VERSION ""

BA_DEF_ SG_ "CSV_ORDER" INT 0 10000;
BA_DEF_DEF_ "CSV_ORDER" 0;

NS_ :

BS_:

BU_:

BO_ 3221225472 VECTOR__INDEPENDENT_SIG_MSG: 0 Vector__XXX
 SG_ ChargerVoltage : 0|16@0+ (0.1,0) [0|6553.5] "" Vector__XXX
 SG_ ChargerCurrent : 0|16@0+ (0.1,0) [0|6553.5] "Amps" Vector__XXX

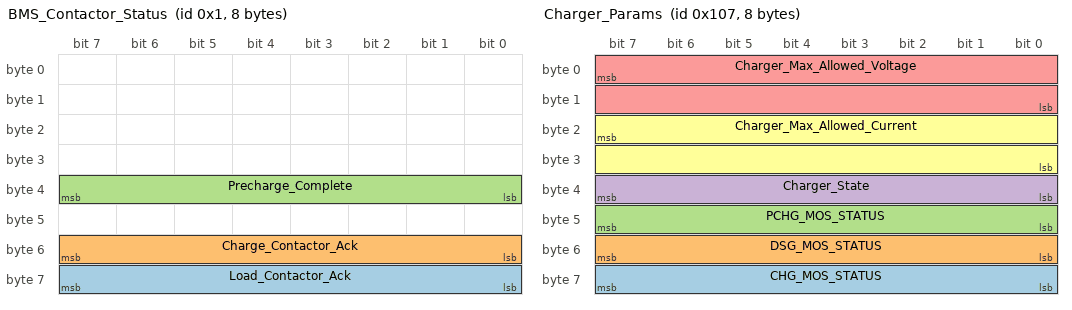
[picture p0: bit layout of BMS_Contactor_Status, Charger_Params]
BO_ 1 BMS_Contactor_Status: 8 Vector__XXX
 SG_ Load_Contactor_Ack : 56|8@1+ (1,0) [0|1] "" Vector__XXX
 SG_ Charge_Contactor_Ack : 48|8@1+ (1,0) [0|1] "" Vector__XXX
 SG_ Precharge_Complete : 32|8@1+ (1,0) [0|1] "" Vector__XXX

BO_ 263 Charger_Params: 8 Vector__XXX
 SG_ CHG_MOS_STATUS : 56|8@1- (1,0) [0|0] "" Vector__XXX
 SG_ DSG_MOS_STATUS : 48|8@1- (1,0) [0|0] "" Vector__XXX
 SG_ PCHG_MOS_STATUS : 40|8@1- (1,0) [0|0] "" Vector__XXX
 SG_ Charger_State : 39|8@0+ (1,0) [0|0] "" Vector__XXX
 SG_ Charger_Max_Allowed_Voltage : 7|16@0+ (0.1,0) [0|0] "V" Vector__XXX
 SG_ Charger_Max_Allowed_Current : 23|16@0+ (0.1,0) [0|0] "A" Vector__XXX

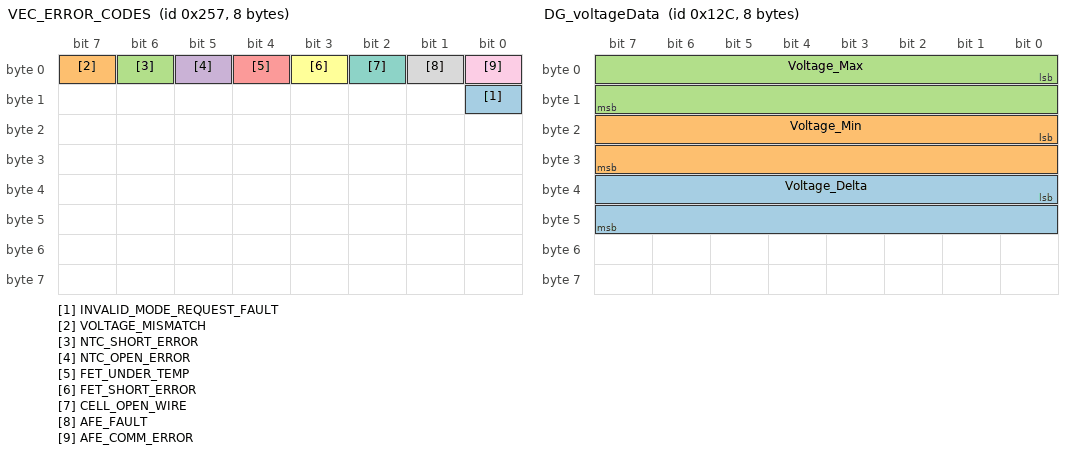
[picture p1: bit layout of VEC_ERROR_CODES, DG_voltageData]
BO_ 599 VEC_ERROR_CODES: 8 Vector__XXX
 SG_ INVALID_MODE_REQUEST_FAULT : 8|1@1+ (1,0) [0|1] "" Vector__XXX
 SG_ VOLTAGE_MISMATCH          : 7|1@1+ (1,0) [0|1] "" Vector__XXX
 SG_ NTC_SHORT_ERROR           : 6|1@1+ (1,0) [0|1] "" Vector__XXX
 SG_ NTC_OPEN_ERROR            : 5|1@1+ (1,0) [0|1] "" Vector__XXX
 SG_ FET_UNDER_TEMP            : 4|1@1+ (1,0) [0|1] "" Vector__XXX
 SG_ FET_SHORT_ERROR           : 3|1@1+ (1,0) [0|1] "" Vector__XXX
 SG_ CELL_OPEN_WIRE            : 2|1@1+ (1,0) [0|1] "" Vector__XXX
 SG_ AFE_FAULT                 : 1|1@1+ (1,0) [0|1] "" Vector__XXX
 SG_ AFE_COMM_ERROR            : 0|1@1+ (1,0) [0|1] "" Vector__XXX

BO_ 336 BalancingMasks: 8 Vector__XXX
 SG_ BalancingMaskGroup1 : 0|8@1+ (1,0) [0|255] "" Vector__XXX
 SG_ BalancingMaskGroup2 : 8|8@1+ (1,0) [0|255] "" Vector__XXX

BO_ 300 DG_voltageData: 8 Vector__XXX
 SG_ Voltage_Delta : 32|16@1+ (0.1,0) [0|65535] "mV" Vector__XXX
 SG_ Voltage_Min : 16|16@1+ (0.1,0) [0|65535] "mV" Vector__XXX
 SG_ Voltage_Max : 0|16@1+ (0.1,0) [0|65535] "mV" Vector__XXX

BO_ 342 BC_Dynamic_inst: 8 Vector__XXX
 SG_ dynamicLimitIn_Inst : 0|16@1- (0.1,0) [-3276.8|3276.7] "" Vector__XXX
 SG_ dynamicLimitOut_Inst : 16|16@1- (0.1,0) [-3276.8|3276.7] "A" Vector__XXX

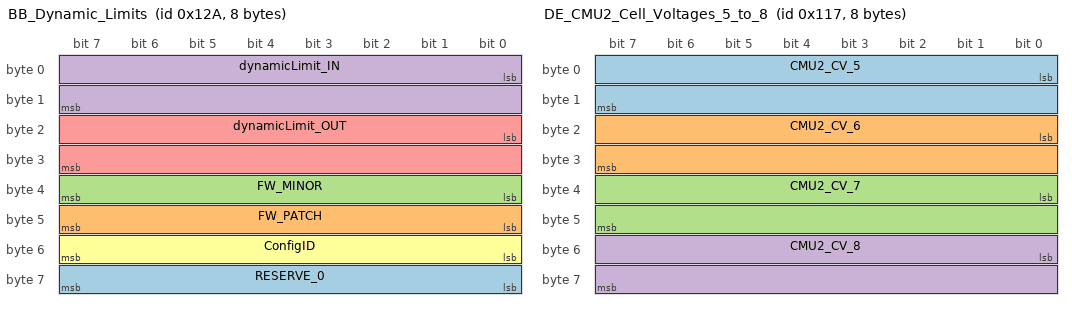
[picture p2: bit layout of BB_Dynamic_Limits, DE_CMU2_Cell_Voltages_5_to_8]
BO_ 298 BB_Dynamic_Limits: 8 Vector__XXX
 SG_ RESERVE_0 : 56|8@1+ (1,0) [0|0] "" Vector__XXX
 SG_ FW_PATCH : 40|8@1+ (1,0) [0|0] "" Vector__XXX
 SG_ FW_MINOR : 32|8@1+ (1,0) [0|0] "" Vector__XXX
 SG_ dynamicLimit_IN : 0|16@1- (0.1,0) [-3276.8|3276.7] "A" Vector__XXX
 SG_ dynamicLimit_OUT : 16|16@1- (0.1,0) [-3276.8|3276.7] "A" Vector__XXX
 SG_ ConfigID : 48|8@1- (1,0) [-128|127] "" Vector__XXX

BO_ 279 DE_CMU2_Cell_Voltages_5_to_8: 8 Vector__XXX
 SG_ CMU2_CV_5 : 0|16@1+ (0.1,0) [0|4200] "mV" Vector__XXX
 SG_ CMU2_CV_6 : 16|16@1+ (0.1,0) [0|4200] "mV" Vector__XXX
 SG_ CMU2_CV_7 : 32|16@1+ (0.1,0) [0|4200] "mV" Vector__XXX
 SG_ CMU2_CV_8 : 48|16@1+ (0.1,0) [0|4200] "mV" Vector__XXX

BO_ 299 BF_CCM_CMU_Counter: 8 Vector__XXX
 SG_ cycleCount : 48|16@1+ (1,0) [0|65535] "" Vector__XXX
 SG_ mcu_counter : 16|16@1+ (1,0) [0|65535] "" Vector__XXX

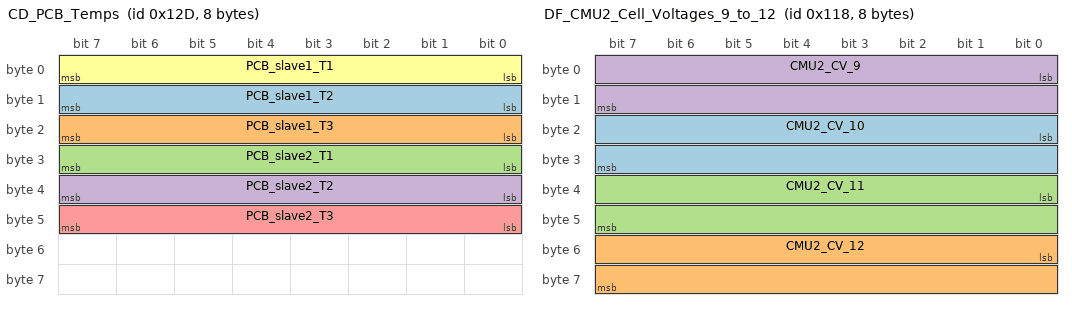
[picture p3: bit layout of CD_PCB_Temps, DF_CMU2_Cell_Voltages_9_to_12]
BO_ 301 CD_PCB_Temps: 8 Vector__XXX
 SG_ PCB_slave1_T2 : 8|8@1- (1,0) [-128|127] "C" Vector__XXX
 SG_ PCB_slave1_T3 : 16|8@1- (1,0) [-128|127] "C" Vector__XXX
 SG_ PCB_slave2_T1 : 24|8@1- (1,0) [-128|127] "C" Vector__XXX
 SG_ PCB_slave2_T2 : 32|8@1- (1,0) [-128|127] "C" Vector__XXX
 SG_ PCB_slave2_T3 : 40|8@1- (1,0) [-128|127] "C" Vector__XXX
 SG_ PCB_slave1_T1 : 0|8@1- (1,0) [-128|127] "C" Vector__XXX

BO_ 280 DF_CMU2_Cell_Voltages_9_to_12: 8 Vector__XXX
 SG_ CMU2_CV_10 : 16|16@1+ (0.1,0) [0|4200] "mV" Vector__XXX
 SG_ CMU2_CV_12 : 48|16@1+ (0.1,0) [0|4200] "mV" Vector__XXX
 SG_ CMU2_CV_11 : 32|16@1+ (0.1,0) [0|4200] "mV" Vector__XXX
 SG_ CMU2_CV_9 : 0|16@1+ (0.1,0) [0|4200] "mV" Vector__XXX

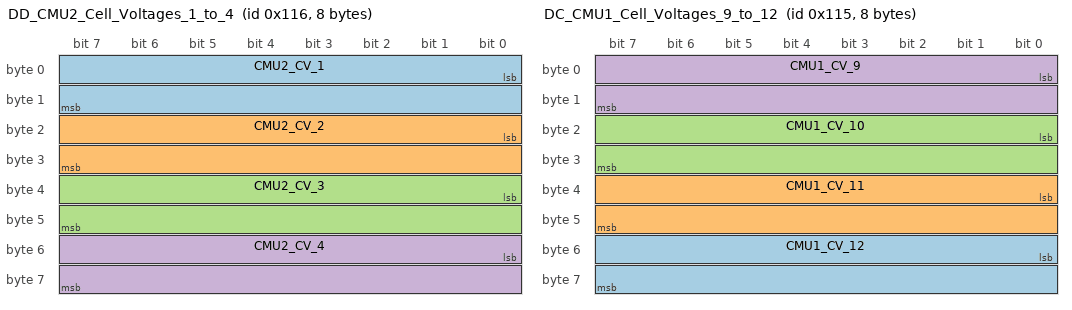
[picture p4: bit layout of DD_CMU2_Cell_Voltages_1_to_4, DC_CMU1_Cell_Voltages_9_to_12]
BO_ 278 DD_CMU2_Cell_Voltages_1_to_4: 8 Vector__XXX
 SG_ CMU2_CV_1 : 0|16@1+ (0.1,0) [0|4200] "mV" Vector__XXX
 SG_ CMU2_CV_2 : 16|16@1+ (0.1,0) [0|4200] "mV" Vector__XXX
 SG_ CMU2_CV_3 : 32|16@1+ (0.1,0) [0|4200] "mV" Vector__XXX
 SG_ CMU2_CV_4 : 48|16@1+ (0.1,0) [0|4200] "mV" Vector__XXX

BO_ 277 DC_CMU1_Cell_Voltages_9_to_12: 8 Vector__XXX
 SG_ CMU1_CV_12 : 48|16@1+ (0.1,0) [0|4200] "mV" Vector__XXX
 SG_ CMU1_CV_11 : 32|16@1+ (0.1,0) [0|4200] "mV" Vector__XXX
 SG_ CMU1_CV_10 : 16|16@1+ (0.1,0) [0|4200] "mV" Vector__XXX
 SG_ CMU1_CV_9 : 0|16@1+ (0.1,0) [0|4200] "mV" Vector__XXX

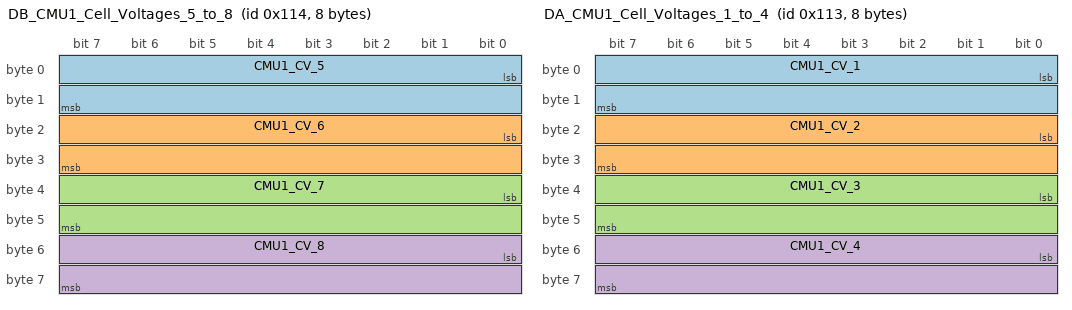
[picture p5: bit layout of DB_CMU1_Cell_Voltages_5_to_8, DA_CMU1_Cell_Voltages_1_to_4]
BO_ 276 DB_CMU1_Cell_Voltages_5_to_8: 8 Vector__XXX
 SG_ CMU1_CV_5 : 0|16@1+ (0.1,0) [0|4200] "mV" Vector__XXX
 SG_ CMU1_CV_6 : 16|16@1+ (0.1,0) [0|4200] "mV" Vector__XXX
 SG_ CMU1_CV_7 : 32|16@1+ (0.1,0) [0|4200] "mV" Vector__XXX
 SG_ CMU1_CV_8 : 48|16@1+ (0.1,0) [0|4200] "mV" Vector__XXX

BO_ 275 DA_CMU1_Cell_Voltages_1_to_4: 8 Vector__XXX
 SG_ CMU1_CV_1 : 0|16@1+ (0.1,0) [0|4200] "mV" Vector__XXX
 SG_ CMU1_CV_2 : 16|16@1+ (0.1,0) [0|4200] "mV" Vector__XXX
 SG_ CMU1_CV_3 : 32|16@1+ (0.1,0) [0|4200] "mV" Vector__XXX
 SG_ CMU1_CV_4 : 48|16@1+ (0.1,0) [0|4200] "mV" Vector__XXX

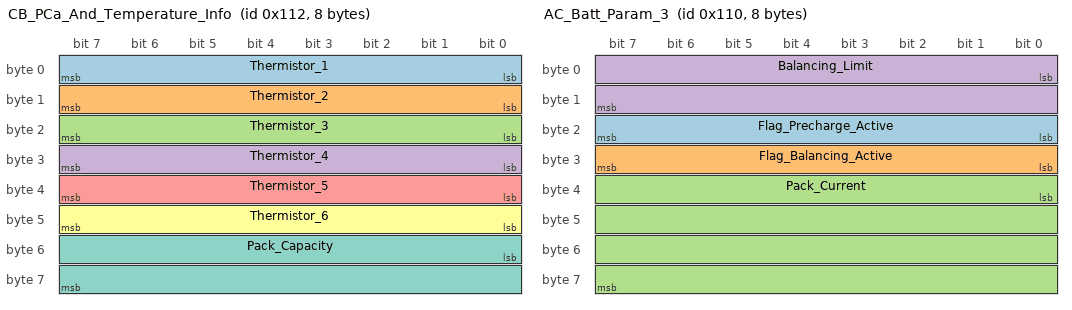
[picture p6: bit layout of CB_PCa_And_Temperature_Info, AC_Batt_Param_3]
BO_ 274 CB_PCa_And_Temperature_Info: 8 Vector__XXX
 SG_ Thermistor_1 : 0|8@1- (1,0) [-128|127] "C" Vector__XXX
 SG_ Thermistor_2 : 8|8@1- (1,0) [-128|127] "C" Vector__XXX
 SG_ Thermistor_3 : 16|8@1- (1,0) [-128|127] "C" Vector__XXX
 SG_ Thermistor_4 : 24|8@1- (1,0) [-128|127] "C" Vector__XXX
 SG_ Thermistor_5 : 32|8@1- (1,0) [-128|127] "C" Vector__XXX
 SG_ Thermistor_6 : 40|8@1- (1,0) [-128|127] "C" Vector__XXX
 SG_ Pack_Capacity : 48|16@1- (0.01,0) [-327.68|327.67] "Ah" Vector__XXX

BO_ 272 AC_Batt_Param_3: 8 Vector__XXX
 SG_ Flag_Precharge_Active : 16|8@1+ (1,0) [0|1] "" Vector__XXX
 SG_ Flag_Balancing_Active : 24|8@1+ (1,0) [0|1] "" Vector__XXX
 SG_ Pack_Current : 32|32@1- (1E-05,0) [-1000|1000] "A" Vector__XXX
 SG_ Balancing_Limit : 0|16@1+ (0.1,0) [0|4200] "mV" Vector__XXX

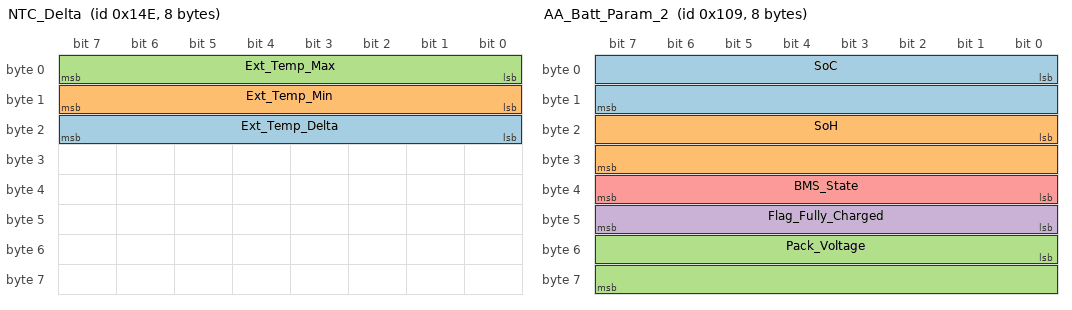
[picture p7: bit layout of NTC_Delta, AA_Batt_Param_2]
BO_ 334 NTC_Delta: 8 Vector__XXX
 SG_ Ext_Temp_Delta : 16|8@1- (1,0) [0|255] "degC" Vector__XXX
 SG_ Ext_Temp_Min   : 8|8@1- (1,0) [0|255] "degC" Vector__XXX
 SG_ Ext_Temp_Max   : 0|8@1- (1,0) [0|255] "degC" Vector__XXX

BO_ 265 AA_Batt_Param_2: 8 Vector__XXX
 SG_ SoC : 0|16@1+ (0.01,0) [0|100] "%" Vector__XXX
 SG_ SoH : 16|16@1+ (0.01,0) [0|100] "%" Vector__XXX
 SG_ Pack_Voltage : 48|16@1+ (0.1,0) [60|85] "V" Vector__XXX
 SG_ Flag_Fully_Charged : 40|8@1+ (1,0) [0|1] "" Vector__XXX
 SG_ BMS_State : 32|8@1+ (1,0) [0|5] "" Vector__XXX

VAL_ 265 Flag_Fully_Charged  0 "False" 1 "True" ;
VAL_ 265 BMS_State           0 "INIT" 1 "Ready" 2 "Precharge" 3 "Active" 4 "Error" ;

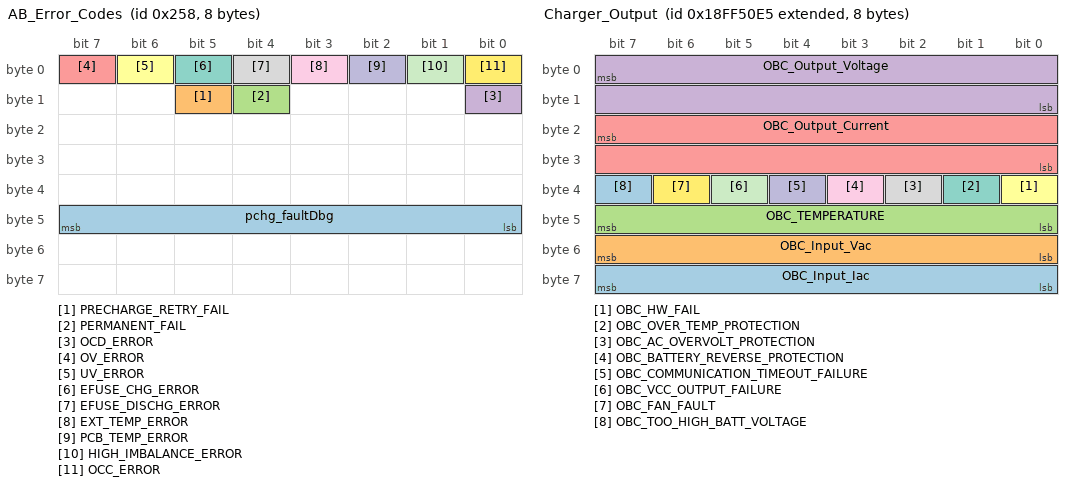
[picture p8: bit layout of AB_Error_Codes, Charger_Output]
BO_ 600 AB_Error_Codes: 8 Vector__XXX
 SG_ pchg_faultDbg          : 40|8@1+ (1,0) [0|255] "" Vector__XXX
 SG_ PRECHARGE_RETRY_FAIL   : 13|1@1+ (1,0) [0|1] "" Vector__XXX
 SG_ PERMANENT_FAIL : 12|1@1+ (1,0) [0|0] "" Vector__XXX
 SG_ OCD_ERROR              : 8|1@1+ (1,0) [0|1] "" Vector__XXX
 SG_ OV_ERROR               : 7|1@1+ (1,0) [0|1] "" Vector__XXX
 SG_ UV_ERROR               : 6|1@1+ (1,0) [0|1] "" Vector__XXX
 SG_ EFUSE_CHG_ERROR        : 5|1@1+ (1,0) [0|1] "" Vector__XXX
 SG_ EFUSE_DISCHG_ERROR     : 4|1@1+ (1,0) [0|1] "" Vector__XXX
 SG_ EXT_TEMP_ERROR         : 3|1@1+ (1,0) [0|1] "" Vector__XXX
 SG_ PCB_TEMP_ERROR         : 2|1@1+ (1,0) [0|1] "" Vector__XXX
 SG_ HIGH_IMBALANCE_ERROR   : 1|1@1+ (1,0) [0|1] "" Vector__XXX
 SG_ OCC_ERROR              : 0|1@1+ (1,0) [0|1] "" Vector__XXX

BO_ 601 Critical_Error: 8 Vector__XXX
 SG_ THERMAL_RUNAWAY : 6|1@1+ (1,0) [0|1] "" Vector__XXX
 SG_ SCD_ERROR : 7|1@1+ (1,0) [0|1] "" Vector__XXX

BO_ 2566869221 Charger_Output: 8 Vector__XXX
 SG_ OBC_Input_Iac : 63|8@0+ (0.1,0) [0|25.5] "A" Vector__XXX
 SG_ OBC_Input_Vac : 55|8@0+ (2,0) [0|510] "V" Vector__XXX
 SG_ OBC_TEMPERATURE : 47|8@0+ (1,-100) [-100|155] "°C" Vector__XXX
 SG_ OBC_Output_Voltage : 7|16@0+ (0.1,0) [0|6553.5] "V" Vector__XXX
 SG_ OBC_Output_Current : 23|16@0+ (0.1,0) [0|6553.5] "A" Vector__XXX
 SG_ OBC_HW_FAIL : 32|1@0- (1,0) [0|1] "" Vector__XXX
 SG_ OBC_OVER_TEMP_PROTECTION : 33|1@0- (1,0) [0|1] "" Vector__XXX
 SG_ OBC_AC_OVERVOLT_PROTECTION : 34|1@0- (1,0) [0|1] "" Vector__XXX
 SG_ OBC_BATTERY_REVERSE_PROTECTION : 35|1@0- (1,0) [0|1] "" Vector__XXX
 SG_ OBC_COMMUNICATION_TIMEOUT_FAILURE : 36|1@0- (1,0) [0|1] "" Vector__XXX
 SG_ OBC_VCC_OUTPUT_FAILURE : 37|1@0- (1,0) [0|1] "" Vector__XXX
 SG_ OBC_FAN_FAULT : 38|1@0- (1,0) [0|1] "" Vector__XXX
 SG_ OBC_TOO_HIGH_BATT_VOLTAGE : 39|1@0- (1,0) [0|1] "" Vector__XXX

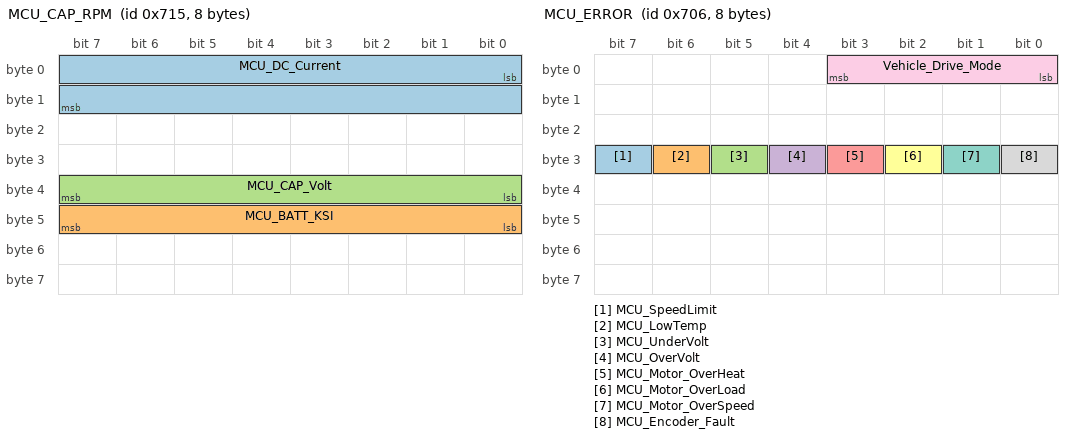
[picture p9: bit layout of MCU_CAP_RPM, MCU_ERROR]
BO_ 1813 MCU_CAP_RPM: 8 Vector__XXX
 SG_ MCU_DC_Current : 0|16@1- (1,0) [-32768|32767] "Adc" Vector__XXX
 SG_ MCU_BATT_KSI : 40|8@1+ (1,0) [0|255] "V" Vector__XXX
 SG_ MCU_CAP_Volt : 32|8@1+ (1,0) [0|255] "V" Vector__XXX

BO_ 1798 MCU_ERROR: 8 Vector__XXX
 SG_ MCU_SpeedLimit : 31|1@1+ (1,0) [0|1] "" Vector__XXX
 SG_ MCU_LowTemp : 30|1@1+ (1,0) [0|1] "" Vector__XXX
 SG_ MCU_UnderVolt : 29|1@1+ (1,0) [0|1] "" Vector__XXX
 SG_ MCU_OverVolt : 28|1@1+ (1,0) [0|1] "" Vector__XXX
 SG_ MCU_Motor_OverHeat : 27|1@1+ (1,0) [0|1] "" Vector__XXX
 SG_ MCU_Motor_OverLoad : 26|1@1+ (1,0) [0|1] "" Vector__XXX
 SG_ MCU_Motor_OverSpeed : 25|1@1+ (1,0) [0|1] "" Vector__XXX
 SG_ MCU_Encoder_Fault : 24|1@1+ (1,0) [0|1] "" Vector__XXX
 SG_ Vehicle_Drive_Mode : 0|4@1+ (1,0) [0|15] "" Vector__XXX

VAL_ 1798 Vehicle_Drive_Mode 1 "NEUTRAL" 2 "ECO" 4 "REVERSE" 8 "THUNDER" ;

BO_ 1800 New_Message_10: 8 Vector__XXX
 SG_ hardware_overvoltage : 10|1@1+ (1,0) [0|1] "" Vector__XXX
 SG_ Hardware_overcurrent : 4|1@1+ (1,0) [0|1] "" Vector__XXX

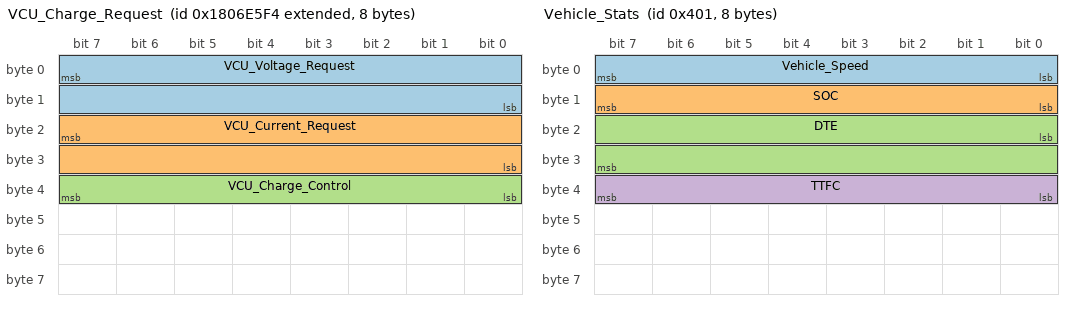
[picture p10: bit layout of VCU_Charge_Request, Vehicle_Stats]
BO_ 2550588916 VCU_Charge_Request: 8 Vector__XXX
 SG_ VCU_Voltage_Request : 7|16@0+ (0.1,0) [0|6553.5] "V" Vector__XXX
 SG_ VCU_Current_Request : 23|16@0+ (0.1,0) [0|6553.5] "A" Vector__XXX
 SG_ VCU_Charge_Control  : 39|8@0+ (1,0) [0|1] "" Vector__XXX

BO_ 1025 Vehicle_Stats: 8 Vector__XXX
 SG_ Vehicle_Speed : 0|8@1+ (1,0) [0|255] "km/h" Vector__XXX
 SG_ SOC           : 8|8@1+ (1,0) [0|100] "%"    Vector__XXX
 SG_ DTE           : 16|16@1+ (0.1,0) [0|6553.5] "min" Vector__XXX
 SG_ TTFC          : 32|8@1+ (1,0) [0|255] "min" Vector__XXX

BO_ 1026 ODO_TRIP: 8 Vector__XXX
 SG_ ODO  : 0|32@1+ (0.1,0) [0|429496729.5] "km" Vector__XXX
 SG_ TRIP : 32|32@1+ (0.1,0) [0|429496729.5] "km" Vector__XXX

BO_ 1033 Odo: 8 Vector__XXX
 SG_ odometer : 7|32@0+ (0.01,0) [0|0] "" Vector__XXX
 SG_ trip : 39|32@0+ (0.01,0) [0|0] "" Vector__XXX

BO_ 1776 Reset: 8 Vector__XXX
 SG_ EcuId : 0|8@1+ (1,0) [0|0] "" Vector__XXX

VAL_ 1776 EcuId 0 "Stark_Reset" 2 "Marvel_Reset" 4 "Xavier_Reset" ;

BO_ 1538 State: 8 Vector__XXX
 SG_ gunConnected : 48|8@1- (1,0) [0|0] "" Vector__XXX
 SG_ VehicleState : 56|8@1+ (1,0) [0|0] "" Vector__XXX

VAL_ 1538 VehicleState           0 "Off" 1 "Charge" 2 "Drive" 3 "Full Charge" 4 "Deep_Sleep/OTA" 5 "Accessories_Mode" ;

BO_ 1542 AuxVoltage: 8 Vector__XXX
 SG_ Aux_Voltage : 15|16@0+ (0.01,0) [0|655.35] "V" Vector__XXX

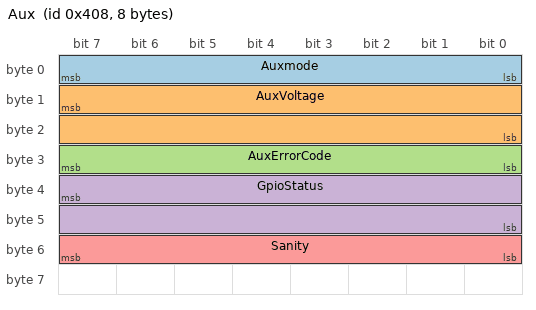
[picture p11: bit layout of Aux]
BO_ 1032 Aux: 8 Vector__XXX
 SG_ Auxmode      : 7|8@0+  (1,0)     [0|255] "" Vector__XXX
 SG_ AuxVoltage   : 15|16@0+ (0.01,0) [0|655.35] "" Vector__XXX
 SG_ AuxErrorCode : 31|8@0+  (1,0)     [0|255] "" Vector__XXX
 SG_ GpioStatus   : 39|16@0+ (1,0)     [0|65535] "" Vector__XXX
 SG_ Sanity       : 55|8@0+  (1,0)     [0|255] "" Vector__XXX

VAL_ 1032 Auxmode 0 "AUX_IDLE" 1 "AUX_CHARGE_START" 2 "AUX_CHARGING" 3 "AUX_SLEEPING" 4 "AUX_ERROR" ;
VAL_ 1032 GpioStatus 0 "ALL_OFF" 1 "(BMS)_ON" 2 "(MCU)_ON" 3 "(BMS+MCU)_ON" 4 "(DC_DC)_ON" 5 "(BMS+DC_DC)_ON" 6 "(MCU+DC_DC)_ON" 7 "(BMS+MCU+DC_DC)_ON" 8 "(HB)_ON" 9 "(BMS+HB)_ON" 10 "(MCU+HB)_ON" 11 "(BMS+MCU+HB)_ON" 12 "(DC_DC+HB)_ON" 13 "(BMS+DC_DC+HB)_ON" 14 "(MCU+DC_DC+HB)_ON" 15 "(BMS+MCU+DC_DC+HB)_ON" 16 "(LB)_ON" 17 "(BMS+LB)_ON" 18 "(MCU+LB)_ON" 19 "(BMS+MCU+LB)_ON" 20 "(DC_DC+LB)_ON" 21 "(BMS+DC_DC+LB)_ON" 22 "(MCU+DC_DC+LB)_ON" 23 "(BMS+MCU+DC_DC+LB)_ON" 24 "(HB+LB)_ON" 25 "(BMS+HB+LB)_ON" 26 "(MCU+HB+LB)_ON" 27 "(BMS+MCU+HB+LB)_ON" 28 "(DC_DC+HB+LB)_ON" 29 "(BMS+DC_DC+HB+LB)_ON" 30 "(MCU+DC_DC+HB+LB)_ON" 31 "(BMS+MCU+DC_DC+HB+LB)_ON" 32 "(CHARGE)_ON" 33 "(BMS+CHARGE)_ON" 34 "(MCU+CHARGE)_ON" 35 "(BMS+MCU+CHARGE)_ON" 36 "(DC_DC+CHARGE)_ON" 37 "(BMS+DC_DC+CHARGE)_ON" 38 "(MCU+DC_DC+CHARGE)_ON" 39 "(BMS+MCU+DC_DC+CHARGE)_ON" 40 "(HB+CHARGE)_ON" 41 "(BMS+HB+CHARGE)_ON" 42 "(MCU+HB+CHARGE)_ON" 43 "(BMS+MCU+HB+CHARGE)_ON" 44 "(DC_DC+HB+CHARGE)_ON" 45 "(BMS+DC_DC+HB+CHARGE)_ON" 46 "(MCU+DC_DC+HB+CHARGE)_ON" 47 "(BMS+MCU+DC_DC+HB+CHARGE)_ON" 48 "(LB+CHARGE)_ON" 49 "(BMS+LB+CHARGE)_ON" 50 "(MCU+LB+CHARGE)_ON" 51 "(BMS+MCU+LB+CHARGE)_ON" 52 "(DC_DC+LB+CHARGE)_ON" 53 "(BMS+DC_DC+LB+CHARGE)_ON" 54 "(MCU+DC_DC+LB+CHARGE)_ON" 55 "(BMS+MCU+DC_DC+LB+CHARGE)_ON" 56 "(HB+LB+CHARGE)_ON" 57 "(BMS+HB+LB+CHARGE)_ON" 58 "(MCU+HB+LB+CHARGE)_ON" 59 "(BMS+MCU+HB+LB+CHARGE)_ON" 60 "(DC_DC+HB+LB+CHARGE)_ON" 61 "(BMS+DC_DC+HB+LB+CHARGE)_ON" 62 "(MCU+DC_DC+HB+LB+CHARGE)_ON" 63 "(BMS+MCU+DC_DC+HB+LB+CHARGE)_ON" 64 "(LOAD)_ON" 65 "(BMS+LOAD)_ON" 66 "(MCU+LOAD)_ON" 67 "(BMS+MCU+LOAD)_ON" 68 "(DC_DC+LOAD)_ON" 69 "(BMS+DC_DC+LOAD)_ON" 70 "(MCU+DC_DC+LOAD)_ON" 71 "(BMS+MCU+DC_DC+LOAD)_ON" 72 "(HB+LOAD)_ON" 73 "(BMS+HB+LOAD)_ON" 74 "(MCU+HB+LOAD)_ON" 75 "(BMS+MCU+HB+LOAD)_ON" 76 "(DC_DC+HB+LOAD)_ON" 77 "(BMS+DC_DC+HB+LOAD)_ON" 78 "(MCU+DC_DC+HB+LOAD)_ON" 79 "(BMS+MCU+DC_DC+HB+LOAD)_ON" 80 "(LB+LOAD)_ON" 81 "(BMS+LB+LOAD)_ON" 82 "(MCU+LB+LOAD)_ON" 83 "(BMS+MCU+LB+LOAD)_ON" 84 "(DC_DC+LB+LOAD)_ON" 85 "(BMS+DC_DC+LB+LOAD)_ON" 86 "(MCU+DC_DC+LB+LOAD)_ON" 87 "(BMS+MCU+DC_DC+LB+LOAD)_ON" 88 "(HB+LB+LOAD)_ON" 89 "(BMS+HB+LB+LOAD)_ON" 90 "(MCU+HB+LB+LOAD)_ON" 91 "(BMS+MCU+HB+LB+LOAD)_ON" 92 "(DC_DC+HB+LB+LOAD)_ON" 93 "(BMS+DC_DC+HB+LB+LOAD)_ON" 94 "(MCU+DC_DC+HB+LB+LOAD)_ON" 95 "(BMS+MCU+DC_DC+HB+LB+LOAD)_ON" 96 "(CHARGE+LOAD)_ON" 97 "(BMS+CHARGE+LOAD)_ON" 98 "(MCU+CHARGE+LOAD)_ON" 99 "(BMS+MCU+CHARGE+LOAD)_ON" 100 "(DC_DC+CHARGE+LOAD)_ON" 101 "(BMS+DC_DC+CHARGE+LOAD)_ON" 102 "(MCU+DC_DC+CHARGE+LOAD)_ON" 103 "(BMS+MCU+DC_DC+CHARGE+LOAD)_ON" 104 "(HB+CHARGE+LOAD)_ON" 105 "(BMS+HB+CHARGE+LOAD)_ON" 106 "(MCU+HB+CHARGE+LOAD)_ON" 107 "(BMS+MCU+HB+CHARGE+LOAD)_ON" 108 "(DC_DC+HB+CHARGE+LOAD)_ON" 109 "(BMS+DC_DC+HB+CHARGE+LOAD)_ON" 110 "(MCU+DC_DC+HB+CHARGE+LOAD)_ON" 111 "(BMS+MCU+DC_DC+HB+CHARGE+LOAD)_ON" 112 "(LB+CHARGE+LOAD)_ON" 113 "(BMS+LB+CHARGE+LOAD)_ON" 114 "(MCU+LB+CHARGE+LOAD)_ON" 115 "(BMS+MCU+LB+CHARGE+LOAD)_ON" 116 "(DC_DC+LB+CHARGE+LOAD)_ON" 117 "(BMS+DC_DC+LB+CHARGE+LOAD)_ON" 118 "(MCU+DC_DC+LB+CHARGE+LOAD)_ON" 119 "(BMS+MCU+DC_DC+LB+CHARGE+LOAD)_ON" 120 "(HB+LB+CHARGE+LOAD)_ON" 121 "(BMS+HB+LB+CHARGE+LOAD)_ON" 122 "(MCU+HB+LB+CHARGE+LOAD)_ON" 123 "(BMS+MCU+HB+LB+CHARGE+LOAD)_ON" 124 "(DC_DC+HB+LB+CHARGE+LOAD)_ON" 125 "(BMS+DC_DC+HB+LB+CHARGE+LOAD)_ON" 126 "(MCU+DC_DC+HB+LB+CHARGE+LOAD)_ON" 127 "(BMS+MCU+DC_DC+HB+LB+CHARGE+LOAD)_ON" 128 "(PARK)_ON" 129 "(BMS+PARK)_ON" 130 "(MCU+PARK)_ON" 131 "(BMS+MCU+PARK)_ON" 132 "(DC_DC+PARK)_ON" 133 "(BMS+DC_DC+PARK)_ON" 134 "(MCU+DC_DC+PARK)_ON" 135 "(BMS+MCU+DC_DC+PARK)_ON" 136 "(HB+PARK)_ON" 137 "(BMS+HB+PARK)_ON" 138 "(MCU+HB+PARK)_ON" 139 "(BMS+MCU+HB+PARK)_ON" 140 "(DC_DC+HB+PARK)_ON" 141 "(BMS+DC_DC+HB+PARK)_ON" 142 "(MCU+DC_DC+HB+PARK)_ON" 143 "(BMS+MCU+DC_DC+HB+PARK)_ON" 144 "(LB+PARK)_ON" 145 "(BMS+LB+PARK)_ON" 146 "(MCU+LB+PARK)_ON" 147 "(BMS+MCU+LB+PARK)_ON" 148 "(DC_DC+LB+PARK)_ON" 149 "(BMS+DC_DC+LB+PARK)_ON" 150 "(MCU+DC_DC+LB+PARK)_ON" 151 "(BMS+MCU+DC_DC+LB+PARK)_ON" 152 "(HB+LB+PARK)_ON" 153 "(BMS+HB+LB+PARK)_ON" 154 "(MCU+HB+LB+PARK)_ON" 155 "(BMS+MCU+HB+LB+PARK)_ON" 156 "(DC_DC+HB+LB+PARK)_ON" 157 "(BMS+DC_DC+HB+LB+PARK)_ON" 158 "(MCU+DC_DC+HB+LB+PARK)_ON" 159 "(BMS+MCU+DC_DC+HB+LB+PARK)_ON" 160 "(CHARGE+PARK)_ON" 161 "(BMS+CHARGE+PARK)_ON" 162 "(MCU+CHARGE+PARK)_ON" 163 "(BMS+MCU+CHARGE+PARK)_ON" 164 "(DC_DC+CHARGE+PARK)_ON" 165 "(BMS+DC_DC+CHARGE+PARK)_ON" 166 "(MCU+DC_DC+CHARGE+PARK)_ON" 167 "(BMS+MCU+DC_DC+CHARGE+PARK)_ON" 168 "(HB+CHARGE+PARK)_ON" 169 "(BMS+HB+CHARGE+PARK)_ON" 170 "(MCU+HB+CHARGE+PARK)_ON" 171 "(BMS+MCU+HB+CHARGE+PARK)_ON" 172 "(DC_DC+HB+CHARGE+PARK)_ON" 173 "(BMS+DC_DC+HB+CHARGE+PARK)_ON" 174 "(MCU+DC_DC+HB+CHARGE+PARK)_ON" 175 "(BMS+MCU+DC_DC+HB+CHARGE+PARK)_ON" 176 "(LB+CHARGE+PARK)_ON" 177 "(BMS+LB+CHARGE+PARK)_ON" 178 "(MCU+LB+CHARGE+PARK)_ON" 179 "(BMS+MCU+LB+CHARGE+PARK)_ON" 180 "(DC_DC+LB+CHARGE+PARK)_ON" 181 "(BMS+DC_DC+LB+CHARGE+PARK)_ON" 182 "(MCU+DC_DC+LB+CHARGE+PARK)_ON" 183 "(BMS+MCU+DC_DC+LB+CHARGE+PARK)_ON" 184 "(HB+LB+CHARGE+PARK)_ON" 185 "(BMS+HB+LB+CHARGE+PARK)_ON" 186 "(MCU+HB+LB+CHARGE+PARK)_ON" 187 "(BMS+MCU+HB+LB+CHARGE+PARK)_ON" 188 "(DC_DC+HB+LB+CHARGE+PARK)_ON" 189 "(BMS+DC_DC+HB+LB+CHARGE+PARK)_ON" 190 "(MCU+DC_DC+HB+LB+CHARGE+PARK)_ON" 191 "(BMS+MCU+DC_DC+HB+LB+CHARGE+PARK)_ON" 192 "(LOAD+PARK)_ON" 193 "(BMS+LOAD+PARK)_ON" 194 "(MCU+LOAD+PARK)_ON" 195 "(BMS+MCU+LOAD+PARK)_ON" 196 "(DC_DC+LOAD+PARK)_ON" 197 "(BMS+DC_DC+LOAD+PARK)_ON" 198 "(MCU+DC_DC+LOAD+PARK)_ON" 199 "(BMS+MCU+DC_DC+LOAD+PARK)_ON" 200 "(HB+LOAD+PARK)_ON" 201 "(BMS+HB+LOAD+PARK)_ON" 202 "(MCU+HB+LOAD+PARK)_ON" 203 "(BMS+MCU+HB+LOAD+PARK)_ON" 204 "(DC_DC+HB+LOAD+PARK)_ON" 205 "(BMS+DC_DC+HB+LOAD+PARK)_ON" 206 "(MCU+DC_DC+HB+LOAD+PARK)_ON" 207 "(BMS+MCU+DC_DC+HB+LOAD+PARK)_ON" 208 "(LB+LOAD+PARK)_ON" 209 "(BMS+LB+LOAD+PARK)_ON" 210 "(MCU+LB+LOAD+PARK)_ON" 211 "(BMS+MCU+LB+LOAD+PARK)_ON" 212 "(DC_DC+LB+LOAD+PARK)_ON" 213 "(BMS+DC_DC+LB+LOAD+PARK)_ON" 214 "(MCU+DC_DC+LB+LOAD+PARK)_ON" 215 "(BMS+MCU+DC_DC+LB+LOAD+PARK)_ON" 216 "(HB+LB+LOAD+PARK)_ON" 217 "(BMS+HB+LB+LOAD+PARK)_ON" 218 "(MCU+HB+LB+LOAD+PARK)_ON" 219 "(BMS+MCU+HB+LB+LOAD+PARK)_ON" 220 "(DC_DC+HB+LB+LOAD+PARK)_ON" 221 "(BMS+DC_DC+HB+LB+LOAD+PARK)_ON" 222 "(MCU+DC_DC+HB+LB+LOAD+PARK)_ON" 223 "(BMS+MCU+DC_DC+HB+LB+LOAD+PARK)_ON" 224 "(CHARGE+LOAD+PARK)_ON" 225 "(BMS+CHARGE+LOAD+PARK)_ON" 226 "(MCU+CHARGE+LOAD+PARK)_ON" 227 "(BMS+MCU+CHARGE+LOAD+PARK)_ON" 228 "(DC_DC+CHARGE+LOAD+PARK)_ON" 229 "(BMS+DC_DC+CHARGE+LOAD+PARK)_ON" 230 "(MCU+DC_DC+CHARGE+LOAD+PARK)_ON" 231 "(BMS+MCU+DC_DC+CHARGE+LOAD+PARK)_ON" 232 "(HB+CHARGE+LOAD+PARK)_ON" 233 "(BMS+HB+CHARGE+LOAD+PARK)_ON" 234 "(MCU+HB+CHARGE+LOAD+PARK)_ON" 235 "(BMS+MCU+HB+CHARGE+LOAD+PARK)_ON" 236 "(DC_DC+HB+CHARGE+LOAD+PARK)_ON" 237 "(BMS+DC_DC+HB+CHARGE+LOAD+PARK)_ON" 238 "(MCU+DC_DC+HB+CHARGE+LOAD+PARK)_ON" 239 "(BMS+MCU+DC_DC+HB+CHARGE+LOAD+PARK)_ON" 240 "(LB+CHARGE+LOAD+PARK)_ON" 241 "(BMS+LB+CHARGE+LOAD+PARK)_ON" 242 "(MCU+LB+CHARGE+LOAD+PARK)_ON" 243 "(BMS+MCU+LB+CHARGE+LOAD+PARK)_ON" 244 "(DC_DC+LB+CHARGE+LOAD+PARK)_ON" 245 "(BMS+DC_DC+LB+CHARGE+LOAD+PARK)_ON" 246 "(MCU+DC_DC+LB+CHARGE+LOAD+PARK)_ON" 247 "(BMS+MCU+DC_DC+LB+CHARGE+LOAD+PARK)_ON" 248 "(HB+LB+CHARGE+LOAD+PARK)_ON" 249 "(BMS+HB+LB+CHARGE+LOAD+PARK)_ON" 250 "(MCU+HB+LB+CHARGE+LOAD+PARK)_ON" 251 "(BMS+MCU+HB+LB+CHARGE+LOAD+PARK)_ON" 252 "(DC_DC+HB+LB+CHARGE+LOAD+PARK)_ON" 253 "(BMS+DC_DC+HB+LB+CHARGE+LOAD+PARK)_ON" 254 "(MCU+DC_DC+HB+LB+CHARGE+LOAD+PARK)_ON" 255 "(BMS+MCU+DC_DC+HB+LB+CHARGE+LOAD+PARK)_ON" 256 "(REVERSE)_ON" 257 "(BMS+REVERSE)_ON" 258 "(MCU+REVERSE)_ON" 259 "(BMS+MCU+REVERSE)_ON" 260 "(DC_DC+REVERSE)_ON" 261 "(BMS+DC_DC+REVERSE)_ON" 262 "(MCU+DC_DC+REVERSE)_ON" 263 "(BMS+MCU+DC_DC+REVERSE)_ON" 264 "(HB+REVERSE)_ON" 265 "(BMS+HB+REVERSE)_ON" 266 "(MCU+HB+REVERSE)_ON" 267 "(BMS+MCU+HB+REVERSE)_ON" 268 "(DC_DC+HB+REVERSE)_ON" 269 "(BMS+DC_DC+HB+REVERSE)_ON" 270 "(MCU+DC_DC+HB+REVERSE)_ON" 271 "(BMS+MCU+DC_DC+HB+REVERSE)_ON" 272 "(LB+REVERSE)_ON" 273 "(BMS+LB+REVERSE)_ON" 274 "(MCU+LB+REVERSE)_ON" 275 "(BMS+MCU+LB+REVERSE)_ON" 276 "(DC_DC+LB+REVERSE)_ON" 277 "(BMS+DC_DC+LB+REVERSE)_ON" 278 "(MCU+DC_DC+LB+REVERSE)_ON" 279 "(BMS+MCU+DC_DC+LB+REVERSE)_ON" 280 "(HB+LB+REVERSE)_ON" 281 "(BMS+HB+LB+REVERSE)_ON" 282 "(MCU+HB+LB+REVERSE)_ON" 283 "(BMS+MCU+HB+LB+REVERSE)_ON" 284 "(DC_DC+HB+LB+REVERSE)_ON" 285 "(BMS+DC_DC+HB+LB+REVERSE)_ON" 286 "(MCU+DC_DC+HB+LB+REVERSE)_ON" 287 "(BMS+MCU+DC_DC+HB+LB+REVERSE)_ON" 288 "(CHARGE+REVERSE)_ON" 289 "(BMS+CHARGE+REVERSE)_ON" 290 "(MCU+CHARGE+REVERSE)_ON" 291 "(BMS+MCU+CHARGE+REVERSE)_ON" 292 "(DC_DC+CHARGE+REVERSE)_ON" 293 "(BMS+DC_DC+CHARGE+REVERSE)_ON" 294 "(MCU+DC_DC+CHARGE+REVERSE)_ON" 295 "(BMS+MCU+DC_DC+CHARGE+REVERSE)_ON" 296 "(HB+CHARGE+REVERSE)_ON" 297 "(BMS+HB+CHARGE+REVERSE)_ON" 298 "(MCU+HB+CHARGE+REVERSE)_ON" 299 "(BMS+MCU+HB+CHARGE+REVERSE)_ON" 300 "(DC_DC+HB+CHARGE+REVERSE)_ON" 301 "(BMS+DC_DC+HB+CHARGE+REVERSE)_ON" 302 "(MCU+DC_DC+HB+CHARGE+REVERSE)_ON" 303 "(BMS+MCU+DC_DC+HB+CHARGE+REVERSE)_ON" 304 "(LB+CHARGE+REVERSE)_ON" 305 "(BMS+LB+CHARGE+REVERSE)_ON" 306 "(MCU+LB+CHARGE+REVERSE)_ON" 307 "(BMS+MCU+LB+CHARGE+REVERSE)_ON" 308 "(DC_DC+LB+CHARGE+REVERSE)_ON" 309 "(BMS+DC_DC+LB+CHARGE+REVERSE)_ON" 310 "(MCU+DC_DC+LB+CHARGE+REVERSE)_ON" 311 "(BMS+MCU+DC_DC+LB+CHARGE+REVERSE)_ON" 312 "(HB+LB+CHARGE+REVERSE)_ON" 313 "(BMS+HB+LB+CHARGE+REVERSE)_ON" 314 "(MCU+HB+LB+CHARGE+REVERSE)_ON" 315 "(BMS+MCU+HB+LB+CHARGE+REVERSE)_ON" 316 "(DC_DC+HB+LB+CHARGE+REVERSE)_ON" 317 "(BMS+DC_DC+HB+LB+CHARGE+REVERSE)_ON" 318 "(MCU+DC_DC+HB+LB+CHARGE+REVERSE)_ON" 319 "(BMS+MCU+DC_DC+HB+LB+CHARGE+REVERSE)_ON" 320 "(LOAD+REVERSE)_ON" 321 "(BMS+LOAD+REVERSE)_ON" 322 "(MCU+LOAD+REVERSE)_ON" 323 "(BMS+MCU+LOAD+REVERSE)_ON" 324 "(DC_DC+LOAD+REVERSE)_ON" 325 "(BMS+DC_DC+LOAD+REVERSE)_ON" 326 "(MCU+DC_DC+LOAD+REVERSE)_ON" 327 "(BMS+MCU+DC_DC+LOAD+REVERSE)_ON" 328 "(HB+LOAD+REVERSE)_ON" 329 "(BMS+HB+LOAD+REVERSE)_ON" 330 "(MCU+HB+LOAD+REVERSE)_ON" 331 "(BMS+MCU+HB+LOAD+REVERSE)_ON" 332 "(DC_DC+HB+LOAD+REVERSE)_ON" 333 "(BMS+DC_DC+HB+LOAD+REVERSE)_ON" 334 "(MCU+DC_DC+HB+LOAD+REVERSE)_ON" 335 "(BMS+MCU+DC_DC+HB+LOAD+REVERSE)_ON" 336 "(LB+LOAD+REVERSE)_ON" 337 "(BMS+LB+LOAD+REVERSE)_ON" 338 "(MCU+LB+LOAD+REVERSE)_ON" 339 "(BMS+MCU+LB+LOAD+REVERSE)_ON" 340 "(DC_DC+LB+LOAD+REVERSE)_ON" 341 "(BMS+DC_DC+LB+LOAD+REVERSE)_ON" 342 "(MCU+DC_DC+LB+LOAD+REVERSE)_ON" 343 "(BMS+MCU+DC_DC+LB+LOAD+REVERSE)_ON" 344 "(HB+LB+LOAD+REVERSE)_ON" 345 "(BMS+HB+LB+LOAD+REVERSE)_ON" 346 "(MCU+HB+LB+LOAD+REVERSE)_ON" 347 "(BMS+MCU+HB+LB+LOAD+REVERSE)_ON" 348 "(DC_DC+HB+LB+LOAD+REVERSE)_ON" 349 "(BMS+DC_DC+HB+LB+LOAD+REVERSE)_ON" 350 "(MCU+DC_DC+HB+LB+LOAD+REVERSE)_ON" 351 "(BMS+MCU+DC_DC+HB+LB+LOAD+REVERSE)_ON" 352 "(CHARGE+LOAD+REVERSE)_ON" 353 "(BMS+CHARGE+LOAD+REVERSE)_ON" 354 "(MCU+CHARGE+LOAD+REVERSE)_ON" 355 "(BMS+MCU+CHARGE+LOAD+REVERSE)_ON" 356 "(DC_DC+CHARGE+LOAD+REVERSE)_ON" 357 "(BMS+DC_DC+CHARGE+LOAD+REVERSE)_ON" 358 "(MCU+DC_DC+CHARGE+LOAD+REVERSE)_ON" 359 "(BMS+MCU+DC_DC+CHARGE+LOAD+REVERSE)_ON" 360 "(HB+CHARGE+LOAD+REVERSE)_ON" 361 "(BMS+HB+CHARGE+LOAD+REVERSE)_ON" 362 "(MCU+HB+CHARGE+LOAD+REVERSE)_ON" 363 "(BMS+MCU+HB+CHARGE+LOAD+REVERSE)_ON" 364 "(DC_DC+HB+CHARGE+LOAD+REVERSE)_ON" 365 "(BMS+DC_DC+HB+CHARGE+LOAD+REVERSE)_ON" 366 "(MCU+DC_DC+HB+CHARGE+LOAD+REVERSE)_ON" 367 "(BMS+MCU+DC_DC+HB+CHARGE+LOAD+REVERSE)_ON" 368 "(LB+CHARGE+LOAD+REVERSE)_ON" 369 "(BMS+LB+CHARGE+LOAD+REVERSE)_ON" 370 "(MCU+LB+CHARGE+LOAD+REVERSE)_ON" 371 "(BMS+MCU+LB+CHARGE+LOAD+REVERSE)_ON" 372 "(DC_DC+LB+CHARGE+LOAD+REVERSE)_ON" 373 "(BMS+DC_DC+LB+CHARGE+LOAD+REVERSE)_ON" 374 "(MCU+DC_DC+LB+CHARGE+LOAD+REVERSE)_ON" 375 "(BMS+MCU+DC_DC+LB+CHARGE+LOAD+REVERSE)_ON" 376 "(HB+LB+CHARGE+LOAD+REVERSE)_ON" 377 "(BMS+HB+LB+CHARGE+LOAD+REVERSE)_ON" 378 "(MCU+HB+LB+CHARGE+LOAD+REVERSE)_ON" 379 "(BMS+MCU+HB+LB+CHARGE+LOAD+REVERSE)_ON" 380 "(DC_DC+HB+LB+CHARGE+LOAD+REVERSE)_ON" 381 "(BMS+DC_DC+HB+LB+CHARGE+LOAD+REVERSE)_ON" 382 "(MCU+DC_DC+HB+LB+CHARGE+LOAD+REVERSE)_ON" 383 "(BMS+MCU+DC_DC+HB+LB+CHARGE+LOAD+REVERSE)_ON" 384 "(PARK+REVERSE)_ON" 385 "(BMS+PARK+REVERSE)_ON" 386 "(MCU+PARK+REVERSE)_ON" 387 "(BMS+MCU+PARK+REVERSE)_ON" 388 "(DC_DC+PARK+REVERSE)_ON" 389 "(BMS+DC_DC+PARK+REVERSE)_ON" 390 "(MCU+DC_DC+PARK+REVERSE)_ON" 391 "(BMS+MCU+DC_DC+PARK+REVERSE)_ON" 392 "(HB+PARK+REVERSE)_ON" 393 "(BMS+HB+PARK+REVERSE)_ON" 394 "(MCU+HB+PARK+REVERSE)_ON" 395 "(BMS+MCU+HB+PARK+REVERSE)_ON" 396 "(DC_DC+HB+PARK+REVERSE)_ON" 397 "(BMS+DC_DC+HB+PARK+REVERSE)_ON" 398 "(MCU+DC_DC+HB+PARK+REVERSE)_ON" 399 "(BMS+MCU+DC_DC+HB+PARK+REVERSE)_ON" 400 "(LB+PARK+REVERSE)_ON" 401 "(BMS+LB+PARK+REVERSE)_ON" 402 "(MCU+LB+PARK+REVERSE)_ON" 403 "(BMS+MCU+LB+PARK+REVERSE)_ON" 404 "(DC_DC+LB+PARK+REVERSE)_ON" 405 "(BMS+DC_DC+LB+PARK+REVERSE)_ON" 406 "(MCU+DC_DC+LB+PARK+REVERSE)_ON" 407 "(BMS+MCU+DC_DC+LB+PARK+REVERSE)_ON" 408 "(HB+LB+PARK+REVERSE)_ON" 409 "(BMS+HB+LB+PARK+REVERSE)_ON" 410 "(MCU+HB+LB+PARK+REVERSE)_ON" 411 "(BMS+MCU+HB+LB+PARK+REVERSE)_ON" 412 "(DC_DC+HB+LB+PARK+REVERSE)_ON" 413 "(BMS+DC_DC+HB+LB+PARK+REVERSE)_ON" 414 "(MCU+DC_DC+HB+LB+PARK+REVERSE)_ON" 415 "(BMS+MCU+DC_DC+HB+LB+PARK+REVERSE)_ON" 416 "(CHARGE+PARK+REVERSE)_ON" 417 "(BMS+CHARGE+PARK+REVERSE)_ON" 418 "(MCU+CHARGE+PARK+REVERSE)_ON" 419 "(BMS+MCU+CHARGE+PARK+REVERSE)_ON" 420 "(DC_DC+CHARGE+PARK+REVERSE)_ON" 421 "(BMS+DC_DC+CHARGE+PARK+REVERSE)_ON" 422 "(MCU+DC_DC+CHARGE+PARK+REVERSE)_ON" 423 "(BMS+MCU+DC_DC+CHARGE+PARK+REVERSE)_ON" 424 "(HB+CHARGE+PARK+REVERSE)_ON" 425 "(BMS+HB+CHARGE+PARK+REVERSE)_ON" 426 "(MCU+HB+CHARGE+PARK+REVERSE)_ON" 427 "(BMS+MCU+HB+CHARGE+PARK+REVERSE)_ON" 428 "(DC_DC+HB+CHARGE+PARK+REVERSE)_ON" 429 "(BMS+DC_DC+HB+CHARGE+PARK+REVERSE)_ON" 430 "(MCU+DC_DC+HB+CHARGE+PARK+REVERSE)_ON" 431 "(BMS+MCU+DC_DC+HB+CHARGE+PARK+REVERSE)_ON" 432 "(LB+CHARGE+PARK+REVERSE)_ON" 433 "(BMS+LB+CHARGE+PARK+REVERSE)_ON" 434 "(MCU+LB+CHARGE+PARK+REVERSE)_ON" 435 "(BMS+MCU+LB+CHARGE+PARK+REVERSE)_ON" 436 "(DC_DC+LB+CHARGE+PARK+REVERSE)_ON" 437 "(BMS+DC_DC+LB+CHARGE+PARK+REVERSE)_ON" 438 "(MCU+DC_DC+LB+CHARGE+PARK+REVERSE)_ON" 439 "(BMS+MCU+DC_DC+LB+CHARGE+PARK+REVERSE)_ON" 440 "(HB+LB+CHARGE+PARK+REVERSE)_ON" 441 "(BMS+HB+LB+CHARGE+PARK+REVERSE)_ON" 442 "(MCU+HB+LB+CHARGE+PARK+REVERSE)_ON" 443 "(BMS+MCU+HB+LB+CHARGE+PARK+REVERSE)_ON" 444 "(DC_DC+HB+LB+CHARGE+PARK+REVERSE)_ON" 445 "(BMS+DC_DC+HB+LB+CHARGE+PARK+REVERSE)_ON" 446 "(MCU+DC_DC+HB+LB+CHARGE+PARK+REVERSE)_ON" 447 "(BMS+MCU+DC_DC+HB+LB+CHARGE+PARK+REVERSE)_ON" 448 "(LOAD+PARK+REVERSE)_ON" 449 "(BMS+LOAD+PARK+REVERSE)_ON" 450 "(MCU+LOAD+PARK+REVERSE)_ON" 451 "(BMS+MCU+LOAD+PARK+REVERSE)_ON" 452 "(DC_DC+LOAD+PARK+REVERSE)_ON" 453 "(BMS+DC_DC+LOAD+PARK+REVERSE)_ON" 454 "(MCU+DC_DC+LOAD+PARK+REVERSE)_ON" 455 "(BMS+MCU+DC_DC+LOAD+PARK+REVERSE)_ON" 456 "(HB+LOAD+PARK+REVERSE)_ON" 457 "(BMS+HB+LOAD+PARK+REVERSE)_ON" 458 "(MCU+HB+LOAD+PARK+REVERSE)_ON" 459 "(BMS+MCU+HB+LOAD+PARK+REVERSE)_ON" 460 "(DC_DC+HB+LOAD+PARK+REVERSE)_ON" 461 "(BMS+DC_DC+HB+LOAD+PARK+REVERSE)_ON" 462 "(MCU+DC_DC+HB+LOAD+PARK+REVERSE)_ON" 463 "(BMS+MCU+DC_DC+HB+LOAD+PARK+REVERSE)_ON" 464 "(LB+LOAD+PARK+REVERSE)_ON" 465 "(BMS+LB+LOAD+PARK+REVERSE)_ON" 466 "(MCU+LB+LOAD+PARK+REVERSE)_ON" 467 "(BMS+MCU+LB+LOAD+PARK+REVERSE)_ON" 468 "(DC_DC+LB+LOAD+PARK+REVERSE)_ON" 469 "(BMS+DC_DC+LB+LOAD+PARK+REVERSE)_ON" 470 "(MCU+DC_DC+LB+LOAD+PARK+REVERSE)_ON" 471 "(BMS+MCU+DC_DC+LB+LOAD+PARK+REVERSE)_ON" 472 "(HB+LB+LOAD+PARK+REVERSE)_ON" 473 "(BMS+HB+LB+LOAD+PARK+REVERSE)_ON" 474 "(MCU+HB+LB+LOAD+PARK+REVERSE)_ON" 475 "(BMS+MCU+HB+LB+LOAD+PARK+REVERSE)_ON" 476 "(DC_DC+HB+LB+LOAD+PARK+REVERSE)_ON" 477 "(BMS+DC_DC+HB+LB+LOAD+PARK+REVERSE)_ON" 478 "(MCU+DC_DC+HB+LB+LOAD+PARK+REVERSE)_ON" 479 "(BMS+MCU+DC_DC+HB+LB+LOAD+PARK+REVERSE)_ON" 480 "(CHARGE+LOAD+PARK+REVERSE)_ON" 481 "(BMS+CHARGE+LOAD+PARK+REVERSE)_ON" 482 "(MCU+CHARGE+LOAD+PARK+REVERSE)_ON" 483 "(BMS+MCU+CHARGE+LOAD+PARK+REVERSE)_ON" 484 "(DC_DC+CHARGE+LOAD+PARK+REVERSE)_ON" 485 "(BMS+DC_DC+CHARGE+LOAD+PARK+REVERSE)_ON" 486 "(MCU+DC_DC+CHARGE+LOAD+PARK+REVERSE)_ON" 487 "(BMS+MCU+DC_DC+CHARGE+LOAD+PARK+REVERSE)_ON" 488 "(HB+CHARGE+LOAD+PARK+REVERSE)_ON" 489 "(BMS+HB+CHARGE+LOAD+PARK+REVERSE)_ON" 490 "(MCU+HB+CHARGE+LOAD+PARK+REVERSE)_ON" 491 "(BMS+MCU+HB+CHARGE+LOAD+PARK+REVERSE)_ON" 492 "(DC_DC+HB+CHARGE+LOAD+PARK+REVERSE)_ON" 493 "(BMS+DC_DC+HB+CHARGE+LOAD+PARK+REVERSE)_ON" 494 "(MCU+DC_DC+HB+CHARGE+LOAD+PARK+REVERSE)_ON" 495 "(BMS+MCU+DC_DC+HB+CHARGE+LOAD+PARK+REVERSE)_ON" 496 "(LB+CHARGE+LOAD+PARK+REVERSE)_ON" 497 "(BMS+LB+CHARGE+LOAD+PARK+REVERSE)_ON" 498 "(MCU+LB+CHARGE+LOAD+PARK+REVERSE)_ON" 499 "(BMS+MCU+LB+CHARGE+LOAD+PARK+REVERSE)_ON" 500 "(DC_DC+LB+CHARGE+LOAD+PARK+REVERSE)_ON" 501 "(BMS+DC_DC+LB+CHARGE+LOAD+PARK+REVERSE)_ON" 502 "(MCU+DC_DC+LB+CHARGE+LOAD+PARK+REVERSE)_ON" 503 "(BMS+MCU+DC_DC+LB+CHARGE+LOAD+PARK+REVERSE)_ON" 504 "(HB+LB+CHARGE+LOAD+PARK+REVERSE)_ON" 505 "(BMS+HB+LB+CHARGE+LOAD+PARK+REVERSE)_ON" 506 "(MCU+HB+LB+CHARGE+LOAD+PARK+REVERSE)_ON" 507 "(BMS+MCU+HB+LB+CHARGE+LOAD+PARK+REVERSE)_ON" 508 "(DC_DC+HB+LB+CHARGE+LOAD+PARK+REVERSE)_ON" 509 "(BMS+DC_DC+HB+LB+CHARGE+LOAD+PARK+REVERSE)_ON" 510 "(MCU+DC_DC+HB+LB+CHARGE+LOAD+PARK+REVERSE)_ON" 511 "(BMS+MCU+DC_DC+HB+LB+CHARGE+LOAD+PARK+REVERSE)_ON" 512 "(DISPLAY)_ON" 513 "(BMS+DISPLAY)_ON" 514 "(MCU+DISPLAY)_ON" 515 "(BMS+MCU+DISPLAY)_ON" 516 "(DC_DC+DISPLAY)_ON" 517 "(BMS+DC_DC+DISPLAY)_ON" 518 "(MCU+DC_DC+DISPLAY)_ON" 519 "(BMS+MCU+DC_DC+DISPLAY)_ON" 520 "(HB+DISPLAY)_ON" 521 "(BMS+HB+DISPLAY)_ON" 522 "(MCU+HB+DISPLAY)_ON" 523 "(BMS+MCU+HB+DISPLAY)_ON" 524 "(DC_DC+HB+DISPLAY)_ON" 525 "(BMS+DC_DC+HB+DISPLAY)_ON" 526 "(MCU+DC_DC+HB+DISPLAY)_ON" 527 "(BMS+MCU+DC_DC+HB+DISPLAY)_ON" 528 "(LB+DISPLAY)_ON" 529 "(BMS+LB+DISPLAY)_ON" 530 "(MCU+LB+DISPLAY)_ON" 531 "(BMS+MCU+LB+DISPLAY)_ON" 532 "(DC_DC+LB+DISPLAY)_ON" 533 "(BMS+DC_DC+LB+DISPLAY)_ON" 534 "(MCU+DC_DC+LB+DISPLAY)_ON" 535 "(BMS+MCU+DC_DC+LB+DISPLAY)_ON" 536 "(HB+LB+DISPLAY)_ON" 537 "(BMS+HB+LB+DISPLAY)_ON" 538 "(MCU+HB+LB+DISPLAY)_ON" 539 "(BMS+MCU+HB+LB+DISPLAY)_ON" 540 "(DC_DC+HB+LB+DISPLAY)_ON" 541 "(BMS+DC_DC+HB+LB+DISPLAY)_ON" 542 "(MCU+DC_DC+HB+LB+DISPLAY)_ON" 543 "(BMS+MCU+DC_DC+HB+LB+DISPLAY)_ON" 544 "(CHARGE+DISPLAY)_ON" 545 "(BMS+CHARGE+DISPLAY)_ON" 546 "(MCU+CHARGE+DISPLAY)_ON" 547 "(BMS+MCU+CHARGE+DISPLAY)_ON" 548 "(DC_DC+CHARGE+DISPLAY)_ON" 549 "(BMS+DC_DC+CHARGE+DISPLAY)_ON" 550 "(MCU+DC_DC+CHARGE+DISPLAY)_ON" 551 "(BMS+MCU+DC_DC+CHARGE+DISPLAY)_ON" 552 "(HB+CHARGE+DISPLAY)_ON" 553 "(BMS+HB+CHARGE+DISPLAY)_ON" 554 "(MCU+HB+CHARGE+DISPLAY)_ON" 555 "(BMS+MCU+HB+CHARGE+DISPLAY)_ON" 556 "(DC_DC+HB+CHARGE+DISPLAY)_ON" 557 "(BMS+DC_DC+HB+CHARGE+DISPLAY)_ON" 558 "(MCU+DC_DC+HB+CHARGE+DISPLAY)_ON" 559 "(BMS+MCU+DC_DC+HB+CHARGE+DISPLAY)_ON" 560 "(LB+CHARGE+DISPLAY)_ON" 561 "(BMS+LB+CHARGE+DISPLAY)_ON" 562 "(MCU+LB+CHARGE+DISPLAY)_ON" 563 "(BMS+MCU+LB+CHARGE+DISPLAY)_ON" 564 "(DC_DC+LB+CHARGE+DISPLAY)_ON" 565 "(BMS+DC_DC+LB+CHARGE+DISPLAY)_ON" 566 "(MCU+DC_DC+LB+CHARGE+DISPLAY)_ON" 567 "(BMS+MCU+DC_DC+LB+CHARGE+DISPLAY)_ON" 568 "(HB+LB+CHARGE+DISPLAY)_ON" 569 "(BMS+HB+LB+CHARGE+DISPLAY)_ON" 570 "(MCU+HB+LB+CHARGE+DISPLAY)_ON" 571 "(BMS+MCU+HB+LB+CHARGE+DISPLAY)_ON" 572 "(DC_DC+HB+LB+CHARGE+DISPLAY)_ON" 573 "(BMS+DC_DC+HB+LB+CHARGE+DISPLAY)_ON" 574 "(MCU+DC_DC+HB+LB+CHARGE+DISPLAY)_ON" 575 "(BMS+MCU+DC_DC+HB+LB+CHARGE+DISPLAY)_ON" 576 "(LOAD+DISPLAY)_ON" 577 "(BMS+LOAD+DISPLAY)_ON" 578 "(MCU+LOAD+DISPLAY)_ON" 579 "(BMS+MCU+LOAD+DISPLAY)_ON" 580 "(DC_DC+LOAD+DISPLAY)_ON" 581 "(BMS+DC_DC+LOAD+DISPLAY)_ON" 582 "(MCU+DC_DC+LOAD+DISPLAY)_ON" 583 "(BMS+MCU+DC_DC+LOAD+DISPLAY)_ON" 584 "(HB+LOAD+DISPLAY)_ON" 585 "(BMS+HB+LOAD+DISPLAY)_ON" 586 "(MCU+HB+LOAD+DISPLAY)_ON" 587 "(BMS+MCU+HB+LOAD+DISPLAY)_ON" 588 "(DC_DC+HB+LOAD+DISPLAY)_ON" 589 "(BMS+DC_DC+HB+LOAD+DISPLAY)_ON" 590 "(MCU+DC_DC+HB+LOAD+DISPLAY)_ON" 591 "(BMS+MCU+DC_DC+HB+LOAD+DISPLAY)_ON" 592 "(LB+LOAD+DISPLAY)_ON" 593 "(BMS+LB+LOAD+DISPLAY)_ON" 594 "(MCU+LB+LOAD+DISPLAY)_ON" 595 "(BMS+MCU+LB+LOAD+DISPLAY)_ON" 596 "(DC_DC+LB+LOAD+DISPLAY)_ON" 597 "(BMS+DC_DC+LB+LOAD+DISPLAY)_ON" 598 "(MCU+DC_DC+LB+LOAD+DISPLAY)_ON" 599 "(BMS+MCU+DC_DC+LB+LOAD+DISPLAY)_ON" 600 "(HB+LB+LOAD+DISPLAY)_ON" 601 "(BMS+HB+LB+LOAD+DISPLAY)_ON" 602 "(MCU+HB+LB+LOAD+DISPLAY)_ON" 603 "(BMS+MCU+HB+LB+LOAD+DISPLAY)_ON" 604 "(DC_DC+HB+LB+LOAD+DISPLAY)_ON" 605 "(BMS+DC_DC+HB+LB+LOAD+DISPLAY)_ON" 606 "(MCU+DC_DC+HB+LB+LOAD+DISPLAY)_ON" 607 "(BMS+MCU+DC_DC+HB+LB+LOAD+DISPLAY)_ON" 608 "(CHARGE+LOAD+DISPLAY)_ON" 609 "(BMS+CHARGE+LOAD+DISPLAY)_ON" 610 "(MCU+CHARGE+LOAD+DISPLAY)_ON" 611 "(BMS+MCU+CHARGE+LOAD+DISPLAY)_ON" 612 "(DC_DC+CHARGE+LOAD+DISPLAY)_ON" 613 "(BMS+DC_DC+CHARGE+LOAD+DISPLAY)_ON" 614 "(MCU+DC_DC+CHARGE+LOAD+DISPLAY)_ON" 615 "(BMS+MCU+DC_DC+CHARGE+LOAD+DISPLAY)_ON" 616 "(HB+CHARGE+LOAD+DISPLAY)_ON" 617 "(BMS+HB+CHARGE+LOAD+DISPLAY)_ON" 618 "(MCU+HB+CHARGE+LOAD+DISPLAY)_ON" 619 "(BMS+MCU+HB+CHARGE+LOAD+DISPLAY)_ON" 620 "(DC_DC+HB+CHARGE+LOAD+DISPLAY)_ON" 621 "(BMS+DC_DC+HB+CHARGE+LOAD+DISPLAY)_ON" 622 "(MCU+DC_DC+HB+CHARGE+LOAD+DISPLAY)_ON" 623 "(BMS+MCU+DC_DC+HB+CHARGE+LOAD+DISPLAY)_ON" 624 "(LB+CHARGE+LOAD+DISPLAY)_ON" 625 "(BMS+LB+CHARGE+LOAD+DISPLAY)_ON" 626 "(MCU+LB+CHARGE+LOAD+DISPLAY)_ON" 627 "(BMS+MCU+LB+CHARGE+LOAD+DISPLAY)_ON" 628 "(DC_DC+LB+CHARGE+LOAD+DISPLAY)_ON" 629 "(BMS+DC_DC+LB+CHARGE+LOAD+DISPLAY)_ON" 630 "(MCU+DC_DC+LB+CHARGE+LOAD+DISPLAY)_ON" 631 "(BMS+MCU+DC_DC+LB+CHARGE+LOAD+DISPLAY)_ON" 632 "(HB+LB+CHARGE+LOAD+DISPLAY)_ON" 633 "(BMS+HB+LB+CHARGE+LOAD+DISPLAY)_ON" 634 "(MCU+HB+LB+CHARGE+LOAD+DISPLAY)_ON" 635 "(BMS+MCU+HB+LB+CHARGE+LOAD+DISPLAY)_ON" 636 "(DC_DC+HB+LB+CHARGE+LOAD+DISPLAY)_ON" 637 "(BMS+DC_DC+HB+LB+CHARGE+LOAD+DISPLAY)_ON" 638 "(MCU+DC_DC+HB+LB+CHARGE+LOAD+DISPLAY)_ON" 639 "(BMS+MCU+DC_DC+HB+LB+CHARGE+LOAD+DISPLAY)_ON" 640 "(PARK+DISPLAY)_ON" 641 "(BMS+PARK+DISPLAY)_ON" 642 "(MCU+PARK+DISPLAY)_ON" 643 "(BMS+MCU+PARK+DISPLAY)_ON" 644 "(DC_DC+PARK+DISPLAY)_ON" 645 "(BMS+DC_DC+PARK+DISPLAY)_ON" 646 "(MCU+DC_DC+PARK+DISPLAY)_ON" 647 "(BMS+MCU+DC_DC+PARK+DISPLAY)_ON" 648 "(HB+PARK+DISPLAY)_ON" 649 "(BMS+HB+PARK+DISPLAY)_ON" 650 "(MCU+HB+PARK+DISPLAY)_ON" 651 "(BMS+MCU+HB+PARK+DISPLAY)_ON" 652 "(DC_DC+HB+PARK+DISPLAY)_ON" 653 "(BMS+DC_DC+HB+PARK+DISPLAY)_ON" 654 "(MCU+DC_DC+HB+PARK+DISPLAY)_ON" 655 "(BMS+MCU+DC_DC+HB+PARK+DISPLAY)_ON" 656 "(LB+PARK+DISPLAY)_ON" 657 "(BMS+LB+PARK+DISPLAY)_ON" 658 "(MCU+LB+PARK+DISPLAY)_ON" 659 "(BMS+MCU+LB+PARK+DISPLAY)_ON" 660 "(DC_DC+LB+PARK+DISPLAY)_ON" 661 "(BMS+DC_DC+LB+PARK+DISPLAY)_ON" 662 "(MCU+DC_DC+LB+PARK+DISPLAY)_ON" 663 "(BMS+MCU+DC_DC+LB+PARK+DISPLAY)_ON" 664 "(HB+LB+PARK+DISPLAY)_ON" 665 "(BMS+HB+LB+PARK+DISPLAY)_ON" 666 "(MCU+HB+LB+PARK+DISPLAY)_ON" 667 "(BMS+MCU+HB+LB+PARK+DISPLAY)_ON" 668 "(DC_DC+HB+LB+PARK+DISPLAY)_ON" 669 "(BMS+DC_DC+HB+LB+PARK+DISPLAY)_ON" 670 "(MCU+DC_DC+HB+LB+PARK+DISPLAY)_ON" 671 "(BMS+MCU+DC_DC+HB+LB+PARK+DISPLAY)_ON" 672 "(CHARGE+PARK+DISPLAY)_ON" 673 "(BMS+CHARGE+PARK+DISPLAY)_ON" 674 "(MCU+CHARGE+PARK+DISPLAY)_ON" 675 "(BMS+MCU+CHARGE+PARK+DISPLAY)_ON" 676 "(DC_DC+CHARGE+PARK+DISPLAY)_ON" 677 "(BMS+DC_DC+CHARGE+PARK+DISPLAY)_ON" 678 "(MCU+DC_DC+CHARGE+PARK+DISPLAY)_ON" 679 "(BMS+MCU+DC_DC+CHARGE+PARK+DISPLAY)_ON" 680 "(HB+CHARGE+PARK+DISPLAY)_ON" 681 "(BMS+HB+CHARGE+PARK+DISPLAY)_ON" 682 "(MCU+HB+CHARGE+PARK+DISPLAY)_ON" 683 "(BMS+MCU+HB+CHARGE+PARK+DISPLAY)_ON" 684 "(DC_DC+HB+CHARGE+PARK+DISPLAY)_ON" 685 "(BMS+DC_DC+HB+CHARGE+PARK+DISPLAY)_ON" 686 "(MCU+DC_DC+HB+CHARGE+PARK+DISPLAY)_ON" 687 "(BMS+MCU+DC_DC+HB+CHARGE+PARK+DISPLAY)_ON" 688 "(LB+CHARGE+PARK+DISPLAY)_ON" 689 "(BMS+LB+CHARGE+PARK+DISPLAY)_ON" 690 "(MCU+LB+CHARGE+PARK+DISPLAY)_ON" 691 "(BMS+MCU+LB+CHARGE+PARK+DISPLAY)_ON" 692 "(DC_DC+LB+CHARGE+PARK+DISPLAY)_ON" 693 "(BMS+DC_DC+LB+CHARGE+PARK+DISPLAY)_ON" 694 "(MCU+DC_DC+LB+CHARGE+PARK+DISPLAY)_ON" 695 "(BMS+MCU+DC_DC+LB+CHARGE+PARK+DISPLAY)_ON" 696 "(HB+LB+CHARGE+PARK+DISPLAY)_ON" 697 "(BMS+HB+LB+CHARGE+PARK+DISPLAY)_ON" 698 "(MCU+HB+LB+CHARGE+PARK+DISPLAY)_ON" 699 "(BMS+MCU+HB+LB+CHARGE+PARK+DISPLAY)_ON" 700 "(DC_DC+HB+LB+CHARGE+PARK+DISPLAY)_ON" 701 "(BMS+DC_DC+HB+LB+CHARGE+PARK+DISPLAY)_ON" 702 "(MCU+DC_DC+HB+LB+CHARGE+PARK+DISPLAY)_ON" 703 "(BMS+MCU+DC_DC+HB+LB+CHARGE+PARK+DISPLAY)_ON" 704 "(LOAD+PARK+DISPLAY)_ON" 705 "(BMS+LOAD+PARK+DISPLAY)_ON" 706 "(MCU+LOAD+PARK+DISPLAY)_ON" 707 "(BMS+MCU+LOAD+PARK+DISPLAY)_ON" 708 "(DC_DC+LOAD+PARK+DISPLAY)_ON" 709 "(BMS+DC_DC+LOAD+PARK+DISPLAY)_ON" 710 "(MCU+DC_DC+LOAD+PARK+DISPLAY)_ON" 711 "(BMS+MCU+DC_DC+LOAD+PARK+DISPLAY)_ON" 712 "(HB+LOAD+PARK+DISPLAY)_ON" 713 "(BMS+HB+LOAD+PARK+DISPLAY)_ON" 714 "(MCU+HB+LOAD+PARK+DISPLAY)_ON" 715 "(BMS+MCU+HB+LOAD+PARK+DISPLAY)_ON" 716 "(DC_DC+HB+LOAD+PARK+DISPLAY)_ON" 717 "(BMS+DC_DC+HB+LOAD+PARK+DISPLAY)_ON" 718 "(MCU+DC_DC+HB+LOAD+PARK+DISPLAY)_ON" 719 "(BMS+MCU+DC_DC+HB+LOAD+PARK+DISPLAY)_ON" 720 "(LB+LOAD+PARK+DISPLAY)_ON" 721 "(BMS+LB+LOAD+PARK+DISPLAY)_ON" 722 "(MCU+LB+LOAD+PARK+DISPLAY)_ON" 723 "(BMS+MCU+LB+LOAD+PARK+DISPLAY)_ON" 724 "(DC_DC+LB+LOAD+PARK+DISPLAY)_ON" 725 "(BMS+DC_DC+LB+LOAD+PARK+DISPLAY)_ON" 726 "(MCU+DC_DC+LB+LOAD+PARK+DISPLAY)_ON" 727 "(BMS+MCU+DC_DC+LB+LOAD+PARK+DISPLAY)_ON" 728 "(HB+LB+LOAD+PARK+DISPLAY)_ON" 729 "(BMS+HB+LB+LOAD+PARK+DISPLAY)_ON" 730 "(MCU+HB+LB+LOAD+PARK+DISPLAY)_ON" 731 "(BMS+MCU+HB+LB+LOAD+PARK+DISPLAY)_ON" 732 "(DC_DC+HB+LB+LOAD+PARK+DISPLAY)_ON" 733 "(BMS+DC_DC+HB+LB+LOAD+PARK+DISPLAY)_ON" 734 "(MCU+DC_DC+HB+LB+LOAD+PARK+DISPLAY)_ON" 735 "(BMS+MCU+DC_DC+HB+LB+LOAD+PARK+DISPLAY)_ON" 736 "(CHARGE+LOAD+PARK+DISPLAY)_ON" 737 "(BMS+CHARGE+LOAD+PARK+DISPLAY)_ON" 738 "(MCU+CHARGE+LOAD+PARK+DISPLAY)_ON" 739 "(BMS+MCU+CHARGE+LOAD+PARK+DISPLAY)_ON" 740 "(DC_DC+CHARGE+LOAD+PARK+DISPLAY)_ON" 741 "(BMS+DC_DC+CHARGE+LOAD+PARK+DISPLAY)_ON" 742 "(MCU+DC_DC+CHARGE+LOAD+PARK+DISPLAY)_ON" 743 "(BMS+MCU+DC_DC+CHARGE+LOAD+PARK+DISPLAY)_ON" 744 "(HB+CHARGE+LOAD+PARK+DISPLAY)_ON" 745 "(BMS+HB+CHARGE+LOAD+PARK+DISPLAY)_ON" 746 "(MCU+HB+CHARGE+LOAD+PARK+DISPLAY)_ON" 747 "(BMS+MCU+HB+CHARGE+LOAD+PARK+DISPLAY)_ON" 748 "(DC_DC+HB+CHARGE+LOAD+PARK+DISPLAY)_ON" 749 "(BMS+DC_DC+HB+CHARGE+LOAD+PARK+DISPLAY)_ON" 750 "(MCU+DC_DC+HB+CHARGE+LOAD+PARK+DISPLAY)_ON" 751 "(BMS+MCU+DC_DC+HB+CHARGE+LOAD+PARK+DISPLAY)_ON" 752 "(LB+CHARGE+LOAD+PARK+DISPLAY)_ON" 753 "(BMS+LB+CHARGE+LOAD+PARK+DISPLAY)_ON" 754 "(MCU+LB+CHARGE+LOAD+PARK+DISPLAY)_ON" 755 "(BMS+MCU+LB+CHARGE+LOAD+PARK+DISPLAY)_ON" 756 "(DC_DC+LB+CHARGE+LOAD+PARK+DISPLAY)_ON" 757 "(BMS+DC_DC+LB+CHARGE+LOAD+PARK+DISPLAY)_ON" 758 "(MCU+DC_DC+LB+CHARGE+LOAD+PARK+DISPLAY)_ON" 759 "(BMS+MCU+DC_DC+LB+CHARGE+LOAD+PARK+DISPLAY)_ON" 760 "(HB+LB+CHARGE+LOAD+PARK+DISPLAY)_ON" 761 "(BMS+HB+LB+CHARGE+LOAD+PARK+DISPLAY)_ON" 762 "(MCU+HB+LB+CHARGE+LOAD+PARK+DISPLAY)_ON" 763 "(BMS+MCU+HB+LB+CHARGE+LOAD+PARK+DISPLAY)_ON" 764 "(DC_DC+HB+LB+CHARGE+LOAD+PARK+DISPLAY)_ON" 765 "(BMS+DC_DC+HB+LB+CHARGE+LOAD+PARK+DISPLAY)_ON" 766 "(MCU+DC_DC+HB+LB+CHARGE+LOAD+PARK+DISPLAY)_ON" 767 "(BMS+MCU+DC_DC+HB+LB+CHARGE+LOAD+PARK+DISPLAY)_ON" 768 "(REVERSE+DISPLAY)_ON" 769 "(BMS+REVERSE+DISPLAY)_ON" 770 "(MCU+REVERSE+DISPLAY)_ON" 771 "(BMS+MCU+REVERSE+DISPLAY)_ON" 772 "(DC_DC+REVERSE+DISPLAY)_ON" 773 "(BMS+DC_DC+REVERSE+DISPLAY)_ON" 774 "(MCU+DC_DC+REVERSE+DISPLAY)_ON" 775 "(BMS+MCU+DC_DC+REVERSE+DISPLAY)_ON" 776 "(HB+REVERSE+DISPLAY)_ON" 777 "(BMS+HB+REVERSE+DISPLAY)_ON" 778 "(MCU+HB+REVERSE+DISPLAY)_ON" 779 "(BMS+MCU+HB+REVERSE+DISPLAY)_ON" 780 "(DC_DC+HB+REVERSE+DISPLAY)_ON" 781 "(BMS+DC_DC+HB+REVERSE+DISPLAY)_ON" 782 "(MCU+DC_DC+HB+REVERSE+DISPLAY)_ON" 783 "(BMS+MCU+DC_DC+HB+REVERSE+DISPLAY)_ON" 784 "(LB+REVERSE+DISPLAY)_ON" 785 "(BMS+LB+REVERSE+DISPLAY)_ON" 786 "(MCU+LB+REVERSE+DISPLAY)_ON" 787 "(BMS+MCU+LB+REVERSE+DISPLAY)_ON" 788 "(DC_DC+LB+REVERSE+DISPLAY)_ON" 789 "(BMS+DC_DC+LB+REVERSE+DISPLAY)_ON" 790 "(MCU+DC_DC+LB+REVERSE+DISPLAY)_ON" 791 "(BMS+MCU+DC_DC+LB+REVERSE+DISPLAY)_ON" 792 "(HB+LB+REVERSE+DISPLAY)_ON" 793 "(BMS+HB+LB+REVERSE+DISPLAY)_ON" 794 "(MCU+HB+LB+REVERSE+DISPLAY)_ON" 795 "(BMS+MCU+HB+LB+REVERSE+DISPLAY)_ON" 796 "(DC_DC+HB+LB+REVERSE+DISPLAY)_ON" 797 "(BMS+DC_DC+HB+LB+REVERSE+DISPLAY)_ON" 798 "(MCU+DC_DC+HB+LB+REVERSE+DISPLAY)_ON" 799 "(BMS+MCU+DC_DC+HB+LB+REVERSE+DISPLAY)_ON" 800 "(CHARGE+REVERSE+DISPLAY)_ON" 801 "(BMS+CHARGE+REVERSE+DISPLAY)_ON" 802 "(MCU+CHARGE+REVERSE+DISPLAY)_ON" 803 "(BMS+MCU+CHARGE+REVERSE+DISPLAY)_ON" 804 "(DC_DC+CHARGE+REVERSE+DISPLAY)_ON" 805 "(BMS+DC_DC+CHARGE+REVERSE+DISPLAY)_ON" 806 "(MCU+DC_DC+CHARGE+REVERSE+DISPLAY)_ON" 807 "(BMS+MCU+DC_DC+CHARGE+REVERSE+DISPLAY)_ON" 808 "(HB+CHARGE+REVERSE+DISPLAY)_ON" 809 "(BMS+HB+CHARGE+REVERSE+DISPLAY)_ON" 810 "(MCU+HB+CHARGE+REVERSE+DISPLAY)_ON" 811 "(BMS+MCU+HB+CHARGE+REVERSE+DISPLAY)_ON" 812 "(DC_DC+HB+CHARGE+REVERSE+DISPLAY)_ON" 813 "(BMS+DC_DC+HB+CHARGE+REVERSE+DISPLAY)_ON" 814 "(MCU+DC_DC+HB+CHARGE+REVERSE+DISPLAY)_ON" 815 "(BMS+MCU+DC_DC+HB+CHARGE+REVERSE+DISPLAY)_ON" 816 "(LB+CHARGE+REVERSE+DISPLAY)_ON" 817 "(BMS+LB+CHARGE+REVERSE+DISPLAY)_ON" 818 "(MCU+LB+CHARGE+REVERSE+DISPLAY)_ON" 819 "(BMS+MCU+LB+CHARGE+REVERSE+DISPLAY)_ON" 820 "(DC_DC+LB+CHARGE+REVERSE+DISPLAY)_ON" 821 "(BMS+DC_DC+LB+CHARGE+REVERSE+DISPLAY)_ON" 822 "(MCU+DC_DC+LB+CHARGE+REVERSE+DISPLAY)_ON" 823 "(BMS+MCU+DC_DC+LB+CHARGE+REVERSE+DISPLAY)_ON" 824 "(HB+LB+CHARGE+REVERSE+DISPLAY)_ON" 825 "(BMS+HB+LB+CHARGE+REVERSE+DISPLAY)_ON" 826 "(MCU+HB+LB+CHARGE+REVERSE+DISPLAY)_ON" 827 "(BMS+MCU+HB+LB+CHARGE+REVERSE+DISPLAY)_ON" 828 "(DC_DC+HB+LB+CHARGE+REVERSE+DISPLAY)_ON" 829 "(BMS+DC_DC+HB+LB+CHARGE+REVERSE+DISPLAY)_ON" 830 "(MCU+DC_DC+HB+LB+CHARGE+REVERSE+DISPLAY)_ON" 831 "(BMS+MCU+DC_DC+HB+LB+CHARGE+REVERSE+DISPLAY)_ON" 832 "(LOAD+REVERSE+DISPLAY)_ON" 833 "(BMS+LOAD+REVERSE+DISPLAY)_ON" 834 "(MCU+LOAD+REVERSE+DISPLAY)_ON" 835 "(BMS+MCU+LOAD+REVERSE+DISPLAY)_ON" 836 "(DC_DC+LOAD+REVERSE+DISPLAY)_ON" 837 "(BMS+DC_DC+LOAD+REVERSE+DISPLAY)_ON" 838 "(MCU+DC_DC+LOAD+REVERSE+DISPLAY)_ON" 839 "(BMS+MCU+DC_DC+LOAD+REVERSE+DISPLAY)_ON" 840 "(HB+LOAD+REVERSE+DISPLAY)_ON" 841 "(BMS+HB+LOAD+REVERSE+DISPLAY)_ON" 842 "(MCU+HB+LOAD+REVERSE+DISPLAY)_ON" 843 "(BMS+MCU+HB+LOAD+REVERSE+DISPLAY)_ON" 844 "(DC_DC+HB+LOAD+REVERSE+DISPLAY)_ON" 845 "(BMS+DC_DC+HB+LOAD+REVERSE+DISPLAY)_ON" 846 "(MCU+DC_DC+HB+LOAD+REVERSE+DISPLAY)_ON" 847 "(BMS+MCU+DC_DC+HB+LOAD+REVERSE+DISPLAY)_ON" 848 "(LB+LOAD+REVERSE+DISPLAY)_ON" 849 "(BMS+LB+LOAD+REVERSE+DISPLAY)_ON" 850 "(MCU+LB+LOAD+REVERSE+DISPLAY)_ON" 851 "(BMS+MCU+LB+LOAD+REVERSE+DISPLAY)_ON" 852 "(DC_DC+LB+LOAD+REVERSE+DISPLAY)_ON" 853 "(BMS+DC_DC+LB+LOAD+REVERSE+DISPLAY)_ON" 854 "(MCU+DC_DC+LB+LOAD+REVERSE+DISPLAY)_ON" 855 "(BMS+MCU+DC_DC+LB+LOAD+REVERSE+DISPLAY)_ON" 856 "(HB+LB+LOAD+REVERSE+DISPLAY)_ON" 857 "(BMS+HB+LB+LOAD+REVERSE+DISPLAY)_ON" 858 "(MCU+HB+LB+LOAD+REVERSE+DISPLAY)_ON" 859 "(BMS+MCU+HB+LB+LOAD+REVERSE+DISPLAY)_ON" 860 "(DC_DC+HB+LB+LOAD+REVERSE+DISPLAY)_ON" 861 "(BMS+DC_DC+HB+LB+LOAD+REVERSE+DISPLAY)_ON" 862 "(MCU+DC_DC+HB+LB+LOAD+REVERSE+DISPLAY)_ON" 863 "(BMS+MCU+DC_DC+HB+LB+LOAD+REVERSE+DISPLAY)_ON" 864 "(CHARGE+LOAD+REVERSE+DISPLAY)_ON" 865 "(BMS+CHARGE+LOAD+REVERSE+DISPLAY)_ON" 866 "(MCU+CHARGE+LOAD+REVERSE+DISPLAY)_ON" 867 "(BMS+MCU+CHARGE+LOAD+REVERSE+DISPLAY)_ON" 868 "(DC_DC+CHARGE+LOAD+REVERSE+DISPLAY)_ON" 869 "(BMS+DC_DC+CHARGE+LOAD+REVERSE+DISPLAY)_ON" 870 "(MCU+DC_DC+CHARGE+LOAD+REVERSE+DISPLAY)_ON" 871 "(BMS+MCU+DC_DC+CHARGE+LOAD+REVERSE+DISPLAY)_ON" 872 "(HB+CHARGE+LOAD+REVERSE+DISPLAY)_ON" 873 "(BMS+HB+CHARGE+LOAD+REVERSE+DISPLAY)_ON" 874 "(MCU+HB+CHARGE+LOAD+REVERSE+DISPLAY)_ON" 875 "(BMS+MCU+HB+CHARGE+LOAD+REVERSE+DISPLAY)_ON" 876 "(DC_DC+HB+CHARGE+LOAD+REVERSE+DISPLAY)_ON" 877 "(BMS+DC_DC+HB+CHARGE+LOAD+REVERSE+DISPLAY)_ON" 878 "(MCU+DC_DC+HB+CHARGE+LOAD+REVERSE+DISPLAY)_ON" 879 "(BMS+MCU+DC_DC+HB+CHARGE+LOAD+REVERSE+DISPLAY)_ON" 880 "(LB+CHARGE+LOAD+REVERSE+DISPLAY)_ON" 881 "(BMS+LB+CHARGE+LOAD+REVERSE+DISPLAY)_ON" 882 "(MCU+LB+CHARGE+LOAD+REVERSE+DISPLAY)_ON" 883 "(BMS+MCU+LB+CHARGE+LOAD+REVERSE+DISPLAY)_ON" 884 "(DC_DC+LB+CHARGE+LOAD+REVERSE+DISPLAY)_ON" 885 "(BMS+DC_DC+LB+CHARGE+LOAD+REVERSE+DISPLAY)_ON" 886 "(MCU+DC_DC+LB+CHARGE+LOAD+REVERSE+DISPLAY)_ON" 887 "(BMS+MCU+DC_DC+LB+CHARGE+LOAD+REVERSE+DISPLAY)_ON" 888 "(HB+LB+CHARGE+LOAD+REVERSE+DISPLAY)_ON" 889 "(BMS+HB+LB+CHARGE+LOAD+REVERSE+DISPLAY)_ON" 890 "(MCU+HB+LB+CHARGE+LOAD+REVERSE+DISPLAY)_ON" 891 "(BMS+MCU+HB+LB+CHARGE+LOAD+REVERSE+DISPLAY)_ON" 892 "(DC_DC+HB+LB+CHARGE+LOAD+REVERSE+DISPLAY)_ON" 893 "(BMS+DC_DC+HB+LB+CHARGE+LOAD+REVERSE+DISPLAY)_ON" 894 "(MCU+DC_DC+HB+LB+CHARGE+LOAD+REVERSE+DISPLAY)_ON" 895 "(BMS+MCU+DC_DC+HB+LB+CHARGE+LOAD+REVERSE+DISPLAY)_ON" 896 "(PARK+REVERSE+DISPLAY)_ON" 897 "(BMS+PARK+REVERSE+DISPLAY)_ON" 898 "(MCU+PARK+REVERSE+DISPLAY)_ON" 899 "(BMS+MCU+PARK+REVERSE+DISPLAY)_ON" 900 "(DC_DC+PARK+REVERSE+DISPLAY)_ON" 901 "(BMS+DC_DC+PARK+REVERSE+DISPLAY)_ON" 902 "(MCU+DC_DC+PARK+REVERSE+DISPLAY)_ON" 903 "(BMS+MCU+DC_DC+PARK+REVERSE+DISPLAY)_ON" 904 "(HB+PARK+REVERSE+DISPLAY)_ON" 905 "(BMS+HB+PARK+REVERSE+DISPLAY)_ON" 906 "(MCU+HB+PARK+REVERSE+DISPLAY)_ON" 907 "(BMS+MCU+HB+PARK+REVERSE+DISPLAY)_ON" 908 "(DC_DC+HB+PARK+REVERSE+DISPLAY)_ON" 909 "(BMS+DC_DC+HB+PARK+REVERSE+DISPLAY)_ON" 910 "(MCU+DC_DC+HB+PARK+REVERSE+DISPLAY)_ON" 911 "(BMS+MCU+DC_DC+HB+PARK+REVERSE+DISPLAY)_ON" 912 "(LB+PARK+REVERSE+DISPLAY)_ON" 913 "(BMS+LB+PARK+REVERSE+DISPLAY)_ON" 914 "(MCU+LB+PARK+REVERSE+DISPLAY)_ON" 915 "(BMS+MCU+LB+PARK+REVERSE+DISPLAY)_ON" 916 "(DC_DC+LB+PARK+REVERSE+DISPLAY)_ON" 917 "(BMS+DC_DC+LB+PARK+REVERSE+DISPLAY)_ON" 918 "(MCU+DC_DC+LB+PARK+REVERSE+DISPLAY)_ON" 919 "(BMS+MCU+DC_DC+LB+PARK+REVERSE+DISPLAY)_ON" 920 "(HB+LB+PARK+REVERSE+DISPLAY)_ON" 921 "(BMS+HB+LB+PARK+REVERSE+DISPLAY)_ON" 922 "(MCU+HB+LB+PARK+REVERSE+DISPLAY)_ON" 923 "(BMS+MCU+HB+LB+PARK+REVERSE+DISPLAY)_ON" 924 "(DC_DC+HB+LB+PARK+REVERSE+DISPLAY)_ON" 925 "(BMS+DC_DC+HB+LB+PARK+REVERSE+DISPLAY)_ON" 926 "(MCU+DC_DC+HB+LB+PARK+REVERSE+DISPLAY)_ON" 927 "(BMS+MCU+DC_DC+HB+LB+PARK+REVERSE+DISPLAY)_ON" 928 "(CHARGE+PARK+REVERSE+DISPLAY)_ON" 929 "(BMS+CHARGE+PARK+REVERSE+DISPLAY)_ON" 930 "(MCU+CHARGE+PARK+REVERSE+DISPLAY)_ON" 931 "(BMS+MCU+CHARGE+PARK+REVERSE+DISPLAY)_ON" 932 "(DC_DC+CHARGE+PARK+REVERSE+DISPLAY)_ON" 933 "(BMS+DC_DC+CHARGE+PARK+REVERSE+DISPLAY)_ON" 934 "(MCU+DC_DC+CHARGE+PARK+REVERSE+DISPLAY)_ON" 935 "(BMS+MCU+DC_DC+CHARGE+PARK+REVERSE+DISPLAY)_ON" 936 "(HB+CHARGE+PARK+REVERSE+DISPLAY)_ON" 937 "(BMS+HB+CHARGE+PARK+REVERSE+DISPLAY)_ON" 938 "(MCU+HB+CHARGE+PARK+REVERSE+DISPLAY)_ON" 939 "(BMS+MCU+HB+CHARGE+PARK+REVERSE+DISPLAY)_ON" 940 "(DC_DC+HB+CHARGE+PARK+REVERSE+DISPLAY)_ON" 941 "(BMS+DC_DC+HB+CHARGE+PARK+REVERSE+DISPLAY)_ON" 942 "(MCU+DC_DC+HB+CHARGE+PARK+REVERSE+DISPLAY)_ON" 943 "(BMS+MCU+DC_DC+HB+CHARGE+PARK+REVERSE+DISPLAY)_ON" 944 "(LB+CHARGE+PARK+REVERSE+DISPLAY)_ON" 945 "(BMS+LB+CHARGE+PARK+REVERSE+DISPLAY)_ON" 946 "(MCU+LB+CHARGE+PARK+REVERSE+DISPLAY)_ON" 947 "(BMS+MCU+LB+CHARGE+PARK+REVERSE+DISPLAY)_ON" 948 "(DC_DC+LB+CHARGE+PARK+REVERSE+DISPLAY)_ON" 949 "(BMS+DC_DC+LB+CHARGE+PARK+REVERSE+DISPLAY)_ON" 950 "(MCU+DC_DC+LB+CHARGE+PARK+REVERSE+DISPLAY)_ON" 951 "(BMS+MCU+DC_DC+LB+CHARGE+PARK+REVERSE+DISPLAY)_ON" 952 "(HB+LB+CHARGE+PARK+REVERSE+DISPLAY)_ON" 953 "(BMS+HB+LB+CHARGE+PARK+REVERSE+DISPLAY)_ON" 954 "(MCU+HB+LB+CHARGE+PARK+REVERSE+DISPLAY)_ON" 955 "(BMS+MCU+HB+LB+CHARGE+PARK+REVERSE+DISPLAY)_ON" 956 "(DC_DC+HB+LB+CHARGE+PARK+REVERSE+DISPLAY)_ON" 957 "(BMS+DC_DC+HB+LB+CHARGE+PARK+REVERSE+DISPLAY)_ON" 958 "(MCU+DC_DC+HB+LB+CHARGE+PARK+REVERSE+DISPLAY)_ON" 959 "(BMS+MCU+DC_DC+HB+LB+CHARGE+PARK+REVERSE+DISPLAY)_ON" 960 "(LOAD+PARK+REVERSE+DISPLAY)_ON" 961 "(BMS+LOAD+PARK+REVERSE+DISPLAY)_ON" 962 "(MCU+LOAD+PARK+REVERSE+DISPLAY)_ON" 963 "(BMS+MCU+LOAD+PARK+REVERSE+DISPLAY)_ON" 964 "(DC_DC+LOAD+PARK+REVERSE+DISPLAY)_ON" 965 "(BMS+DC_DC+LOAD+PARK+REVERSE+DISPLAY)_ON" 966 "(MCU+DC_DC+LOAD+PARK+REVERSE+DISPLAY)_ON" 967 "(BMS+MCU+DC_DC+LOAD+PARK+REVERSE+DISPLAY)_ON" 968 "(HB+LOAD+PARK+REVERSE+DISPLAY)_ON" 969 "(BMS+HB+LOAD+PARK+REVERSE+DISPLAY)_ON" 970 "(MCU+HB+LOAD+PARK+REVERSE+DISPLAY)_ON" 971 "(BMS+MCU+HB+LOAD+PARK+REVERSE+DISPLAY)_ON" 972 "(DC_DC+HB+LOAD+PARK+REVERSE+DISPLAY)_ON" 973 "(BMS+DC_DC+HB+LOAD+PARK+REVERSE+DISPLAY)_ON" 974 "(MCU+DC_DC+HB+LOAD+PARK+REVERSE+DISPLAY)_ON" 975 "(BMS+MCU+DC_DC+HB+LOAD+PARK+REVERSE+DISPLAY)_ON" 976 "(LB+LOAD+PARK+REVERSE+DISPLAY)_ON" 977 "(BMS+LB+LOAD+PARK+REVERSE+DISPLAY)_ON" 978 "(MCU+LB+LOAD+PARK+REVERSE+DISPLAY)_ON" 979 "(BMS+MCU+LB+LOAD+PARK+REVERSE+DISPLAY)_ON" 980 "(DC_DC+LB+LOAD+PARK+REVERSE+DISPLAY)_ON" 981 "(BMS+DC_DC+LB+LOAD+PARK+REVERSE+DISPLAY)_ON" 982 "(MCU+DC_DC+LB+LOAD+PARK+REVERSE+DISPLAY)_ON" 983 "(BMS+MCU+DC_DC+LB+LOAD+PARK+REVERSE+DISPLAY)_ON" 984 "(HB+LB+LOAD+PARK+REVERSE+DISPLAY)_ON" 985 "(BMS+HB+LB+LOAD+PARK+REVERSE+DISPLAY)_ON" 986 "(MCU+HB+LB+LOAD+PARK+REVERSE+DISPLAY)_ON" 987 "(BMS+MCU+HB+LB+LOAD+PARK+REVERSE+DISPLAY)_ON" 988 "(DC_DC+HB+LB+LOAD+PARK+REVERSE+DISPLAY)_ON" 989 "(BMS+DC_DC+HB+LB+LOAD+PARK+REVERSE+DISPLAY)_ON" 990 "(MCU+DC_DC+HB+LB+LOAD+PARK+REVERSE+DISPLAY)_ON" 991 "(BMS+MCU+DC_DC+HB+LB+LOAD+PARK+REVERSE+DISPLAY)_ON" 992 "(CHARGE+LOAD+PARK+REVERSE+DISPLAY)_ON" 993 "(BMS+CHARGE+LOAD+PARK+REVERSE+DISPLAY)_ON" 994 "(MCU+CHARGE+LOAD+PARK+REVERSE+DISPLAY)_ON" 995 "(BMS+MCU+CHARGE+LOAD+PARK+REVERSE+DISPLAY)_ON" 996 "(DC_DC+CHARGE+LOAD+PARK+REVERSE+DISPLAY)_ON" 997 "(BMS+DC_DC+CHARGE+LOAD+PARK+REVERSE+DISPLAY)_ON" 998 "(MCU+DC_DC+CHARGE+LOAD+PARK+REVERSE+DISPLAY)_ON" 999 "(BMS+MCU+DC_DC+CHARGE+LOAD+PARK+REVERSE+DISPLAY)_ON" 1000 "(HB+CHARGE+LOAD+PARK+REVERSE+DISPLAY)_ON" 1001 "(BMS+HB+CHARGE+LOAD+PARK+REVERSE+DISPLAY)_ON" 1002 "(MCU+HB+CHARGE+LOAD+PARK+REVERSE+DISPLAY)_ON" 1003 "(BMS+MCU+HB+CHARGE+LOAD+PARK+REVERSE+DISPLAY)_ON" 1004 "(DC_DC+HB+CHARGE+LOAD+PARK+REVERSE+DISPLAY)_ON" 1005 "(BMS+DC_DC+HB+CHARGE+LOAD+PARK+REVERSE+DISPLAY)_ON" 1006 "(MCU+DC_DC+HB+CHARGE+LOAD+PARK+REVERSE+DISPLAY)_ON" 1007 "(BMS+MCU+DC_DC+HB+CHARGE+LOAD+PARK+REVERSE+DISPLAY)_ON" 1008 "(LB+CHARGE+LOAD+PARK+REVERSE+DISPLAY)_ON" 1009 "(BMS+LB+CHARGE+LOAD+PARK+REVERSE+DISPLAY)_ON" 1010 "(MCU+LB+CHARGE+LOAD+PARK+REVERSE+DISPLAY)_ON" 1011 "(BMS+MCU+LB+CHARGE+LOAD+PARK+REVERSE+DISPLAY)_ON" 1012 "(DC_DC+LB+CHARGE+LOAD+PARK+REVERSE+DISPLAY)_ON" 1013 "(BMS+DC_DC+LB+CHARGE+LOAD+PARK+REVERSE+DISPLAY)_ON" 1014 "(MCU+DC_DC+LB+CHARGE+LOAD+PARK+REVERSE+DISPLAY)_ON" 1015 "(BMS+MCU+DC_DC+LB+CHARGE+LOAD+PARK+REVERSE+DISPLAY)_ON" 1016 "(HB+LB+CHARGE+LOAD+PARK+REVERSE+DISPLAY)_ON" 1017 "(BMS+HB+LB+CHARGE+LOAD+PARK+REVERSE+DISPLAY)_ON" 1018 "(MCU+HB+LB+CHARGE+LOAD+PARK+REVERSE+DISPLAY)_ON" 1019 "(BMS+MCU+HB+LB+CHARGE+LOAD+PARK+REVERSE+DISPLAY)_ON" 1020 "(DC_DC+HB+LB+CHARGE+LOAD+PARK+REVERSE+DISPLAY)_ON" 1021 "(BMS+DC_DC+HB+LB+CHARGE+LOAD+PARK+REVERSE+DISPLAY)_ON" 1022 "(MCU+DC_DC+HB+LB+CHARGE+LOAD+PARK+REVERSE+DISPLAY)_ON" 1023 "(BMS+MCU+DC_DC+HB+LB+CHARGE+LOAD+PARK+REVERSE+DISPLAY)_ON" ;

BO_ 1571 BMS_Status: 8 Vector__XXX

BA_ "CSV_ORDER" SG_ 1542 Aux_Voltage 1;
BA_ "CSV_ORDER" SG_ 1032 AuxVoltage 2;
BA_ "CSV_ORDER" SG_ 1025 SOC 3;
BA_ "CSV_ORDER" SG_ 265 SoC 4;
BA_ "CSV_ORDER" SG_ 265 SoH 5;
BA_ "CSV_ORDER" SG_ 1538 VehicleState 6;
BA_ "CSV_ORDER" SG_ 265 BMS_State 7;
BA_ "CSV_ORDER" SG_ 1032 GpioStatus 9;
BA_ "CSV_ORDER" SG_ 272 Pack_Current 10;
BA_ "CSV_ORDER" SG_ 274 Pack_Capacity 11;
BA_ "CSV_ORDER" SG_ 265 Pack_Voltage 12;
BA_ "CSV_ORDER" SG_ 298 dynamicLimit_IN 13;
BA_ "CSV_ORDER" SG_ 298 dynamicLimit_OUT 14;
BA_ "CSV_ORDER" SG_ 342 dynamicLimitIn_Inst 15;
BA_ "CSV_ORDER" SG_ 342 dynamicLimitOut_Inst 16;
BA_ "CSV_ORDER" SG_ 1 Charge_Contactor_Ack 17;
BA_ "CSV_ORDER" SG_ 263 CHG_MOS_STATUS 18;
BA_ "CSV_ORDER" SG_ 1 Load_Contactor_Ack 19;
BA_ "CSV_ORDER" SG_ 263 DSG_MOS_STATUS 20;
BA_ "CSV_ORDER" SG_ 272 Flag_Precharge_Active 21;
BA_ "CSV_ORDER" SG_ 263 PCHG_MOS_STATUS 22;
BA_ "CSV_ORDER" SG_ 1 Precharge_Complete 23;
BA_ "CSV_ORDER" SG_ 265 Flag_Fully_Charged 24;
BA_ "CSV_ORDER" SG_ 272 Flag_Balancing_Active 25;
BA_ "CSV_ORDER" SG_ 272 Balancing_Limit 26;
BA_ "CSV_ORDER" SG_ 300 Voltage_Max 29;
BA_ "CSV_ORDER" SG_ 300 Voltage_Min 30;
BA_ "CSV_ORDER" SG_ 300 Voltage_Delta 31;
BA_ "CSV_ORDER" SG_ 275 CMU1_CV_1 32;
BA_ "CSV_ORDER" SG_ 275 CMU1_CV_2 33;
BA_ "CSV_ORDER" SG_ 275 CMU1_CV_3 34;
BA_ "CSV_ORDER" SG_ 275 CMU1_CV_4 35;
BA_ "CSV_ORDER" SG_ 276 CMU1_CV_5 36;
BA_ "CSV_ORDER" SG_ 276 CMU1_CV_6 37;
BA_ "CSV_ORDER" SG_ 276 CMU1_CV_7 38;
BA_ "CSV_ORDER" SG_ 276 CMU1_CV_8 39;
BA_ "CSV_ORDER" SG_ 277 CMU1_CV_9 40;
BA_ "CSV_ORDER" SG_ 277 CMU1_CV_10 41;
BA_ "CSV_ORDER" SG_ 277 CMU1_CV_11 42;
BA_ "CSV_ORDER" SG_ 277 CMU1_CV_12 43;
BA_ "CSV_ORDER" SG_ 278 CMU2_CV_1 44;
BA_ "CSV_ORDER" SG_ 278 CMU2_CV_2 45;
BA_ "CSV_ORDER" SG_ 278 CMU2_CV_3 46;
BA_ "CSV_ORDER" SG_ 278 CMU2_CV_4 47;
BA_ "CSV_ORDER" SG_ 279 CMU2_CV_5 48;
BA_ "CSV_ORDER" SG_ 279 CMU2_CV_6 49;
BA_ "CSV_ORDER" SG_ 279 CMU2_CV_7 50;
BA_ "CSV_ORDER" SG_ 279 CMU2_CV_8 51;
BA_ "CSV_ORDER" SG_ 280 CMU2_CV_9 52;
BA_ "CSV_ORDER" SG_ 280 CMU2_CV_10 53;
BA_ "CSV_ORDER" SG_ 280 CMU2_CV_11 54;
BA_ "CSV_ORDER" SG_ 280 CMU2_CV_12 55;
BA_ "CSV_ORDER" SG_ 334 Ext_Temp_Max 56;
BA_ "CSV_ORDER" SG_ 334 Ext_Temp_Min 57;
BA_ "CSV_ORDER" SG_ 334 Ext_Temp_Delta 58;
BA_ "CSV_ORDER" SG_ 274 Thermistor_1 59;
BA_ "CSV_ORDER" SG_ 274 Thermistor_2 60;
BA_ "CSV_ORDER" SG_ 274 Thermistor_3 61;
BA_ "CSV_ORDER" SG_ 274 Thermistor_4 62;
BA_ "CSV_ORDER" SG_ 274 Thermistor_5 63;
BA_ "CSV_ORDER" SG_ 274 Thermistor_6 64;
BA_ "CSV_ORDER" SG_ 301 PCB_slave1_T1 65;
BA_ "CSV_ORDER" SG_ 301 PCB_slave1_T2 66;
BA_ "CSV_ORDER" SG_ 301 PCB_slave1_T3 67;
BA_ "CSV_ORDER" SG_ 301 PCB_slave2_T1 68;
BA_ "CSV_ORDER" SG_ 301 PCB_slave2_T2 69;
BA_ "CSV_ORDER" SG_ 301 PCB_slave2_T3 70;
BA_ "CSV_ORDER" SG_ 263 Charger_Max_Allowed_Current 71;
BA_ "CSV_ORDER" SG_ 263 Charger_Max_Allowed_Voltage 72;
BA_ "CSV_ORDER" SG_ 299 cycleCount 73;
BA_ "CSV_ORDER" SG_ 263 Charger_State 74;
BA_ "CSV_ORDER" SG_ 2550588916 VCU_Current_Request 75;
BA_ "CSV_ORDER" SG_ 2550588916 VCU_Charge_Control 76;
BA_ "CSV_ORDER" SG_ 2550588916 VCU_Voltage_Request 77;
BA_ "CSV_ORDER" SG_ 1538 gunConnected 78;
BA_ "CSV_ORDER" SG_ 1026 TRIP 79;
BA_ "CSV_ORDER" SG_ 1033 trip 80;
BA_ "CSV_ORDER" SG_ 1025 Vehicle_Speed 81;
BA_ "CSV_ORDER" SG_ 1798 Vehicle_Drive_Mode 82;
BA_ "CSV_ORDER" SG_ 1026 ODO 83;
BA_ "CSV_ORDER" SG_ 1033 odometer 84;
BA_ "CSV_ORDER" SG_ 1025 DTE 85;
BA_ "CSV_ORDER" SG_ 1776 EcuId 86;
BA_ "CSV_ORDER" SG_ 1032 Auxmode 87;
BA_ "CSV_ORDER" SG_ 1032 AuxErrorCode 88;
BA_ "CSV_ORDER" SG_ 1032 Sanity 89;
BA_ "CSV_ORDER" SG_ 1025 TTFC 90;
BA_ "CSV_ORDER" SG_ 298 FW_MINOR 91;
BA_ "CSV_ORDER" SG_ 298 FW_PATCH 92;
BA_ "CSV_ORDER" SG_ 298 ConfigID 93;
BA_ "CSV_ORDER" SG_ 599 INVALID_MODE_REQUEST_FAULT 94;
BA_ "CSV_ORDER" SG_ 599 AFE_COMM_ERROR 95;
BA_ "CSV_ORDER" SG_ 599 AFE_FAULT 96;
BA_ "CSV_ORDER" SG_ 599 CELL_OPEN_WIRE 97;
BA_ "CSV_ORDER" SG_ 599 FET_SHORT_ERROR 98;
BA_ "CSV_ORDER" SG_ 599 FET_UNDER_TEMP 99;
BA_ "CSV_ORDER" SG_ 599 NTC_OPEN_ERROR 100;
BA_ "CSV_ORDER" SG_ 599 NTC_SHORT_ERROR 101;
BA_ "CSV_ORDER" SG_ 599 VOLTAGE_MISMATCH 102;
BA_ "CSV_ORDER" SG_ 600 PRECHARGE_RETRY_FAIL 103;
BA_ "CSV_ORDER" SG_ 600 EFUSE_CHG_ERROR 104;
BA_ "CSV_ORDER" SG_ 600 EFUSE_DISCHG_ERROR 105;
BA_ "CSV_ORDER" SG_ 600 EXT_TEMP_ERROR 106;
BA_ "CSV_ORDER" SG_ 600 HIGH_IMBALANCE_ERROR 107;
BA_ "CSV_ORDER" SG_ 600 OCC_ERROR 108;
BA_ "CSV_ORDER" SG_ 600 PERMANENT_FAIL 109;
BA_ "CSV_ORDER" SG_ 600 OCD_ERROR 110;
BA_ "CSV_ORDER" SG_ 600 OV_ERROR 111;
BA_ "CSV_ORDER" SG_ 600 PCB_TEMP_ERROR 112;
BA_ "CSV_ORDER" SG_ 600 pchg_faultDbg 113;
BA_ "CSV_ORDER" SG_ 600 UV_ERROR 114;
BA_ "CSV_ORDER" SG_ 601 SCD_ERROR 115;
BA_ "CSV_ORDER" SG_ 601 THERMAL_RUNAWAY 116;
BA_ "CSV_ORDER" SG_ 299 mcu_counter 117;
BA_ "CSV_ORDER" SG_ 298 RESERVE_0 118;
BA_ "CSV_ORDER" SG_ 1800 Hardware_overcurrent 119;
BA_ "CSV_ORDER" SG_ 1800 hardware_overvoltage 120;
BA_ "CSV_ORDER" SG_ 1813 MCU_BATT_KSI 121;
BA_ "CSV_ORDER" SG_ 1813 MCU_CAP_Volt 122;
BA_ "CSV_ORDER" SG_ 1813 MCU_DC_Current 123;
BA_ "CSV_ORDER" SG_ 1798 MCU_Encoder_Fault 124;
BA_ "CSV_ORDER" SG_ 1798 MCU_LowTemp 125;
BA_ "CSV_ORDER" SG_ 1798 MCU_Motor_OverHeat 126;
BA_ "CSV_ORDER" SG_ 1798 MCU_Motor_OverLoad 127;
BA_ "CSV_ORDER" SG_ 1798 MCU_Motor_OverSpeed 128;
BA_ "CSV_ORDER" SG_ 1798 MCU_OverVolt 129;
BA_ "CSV_ORDER" SG_ 1798 MCU_SpeedLimit 130;
BA_ "CSV_ORDER" SG_ 1798 MCU_UnderVolt 131;
BA_ "CSV_ORDER" SG_ 2566869221 OBC_AC_OVERVOLT_PROTECTION 132;
BA_ "CSV_ORDER" SG_ 2566869221 OBC_BATTERY_REVERSE_PROTECTION 133;
BA_ "CSV_ORDER" SG_ 2566869221 OBC_COMMUNICATION_TIMEOUT_FAILURE 134;
BA_ "CSV_ORDER" SG_ 2566869221 OBC_FAN_FAULT 135;
BA_ "CSV_ORDER" SG_ 2566869221 OBC_HW_FAIL 136;
BA_ "CSV_ORDER" SG_ 2566869221 OBC_Input_Iac 137;
BA_ "CSV_ORDER" SG_ 2566869221 OBC_Input_Vac 138;
BA_ "CSV_ORDER" SG_ 2566869221 OBC_Output_Current 139;
BA_ "CSV_ORDER" SG_ 2566869221 OBC_Output_Voltage 140;
BA_ "CSV_ORDER" SG_ 2566869221 OBC_OVER_TEMP_PROTECTION 141;
BA_ "CSV_ORDER" SG_ 2566869221 OBC_TEMPERATURE 142;
BA_ "CSV_ORDER" SG_ 2566869221 OBC_TOO_HIGH_BATT_VOLTAGE 143;
BA_ "CSV_ORDER" SG_ 2566869221 OBC_VCC_OUTPUT_FAILURE 144;
